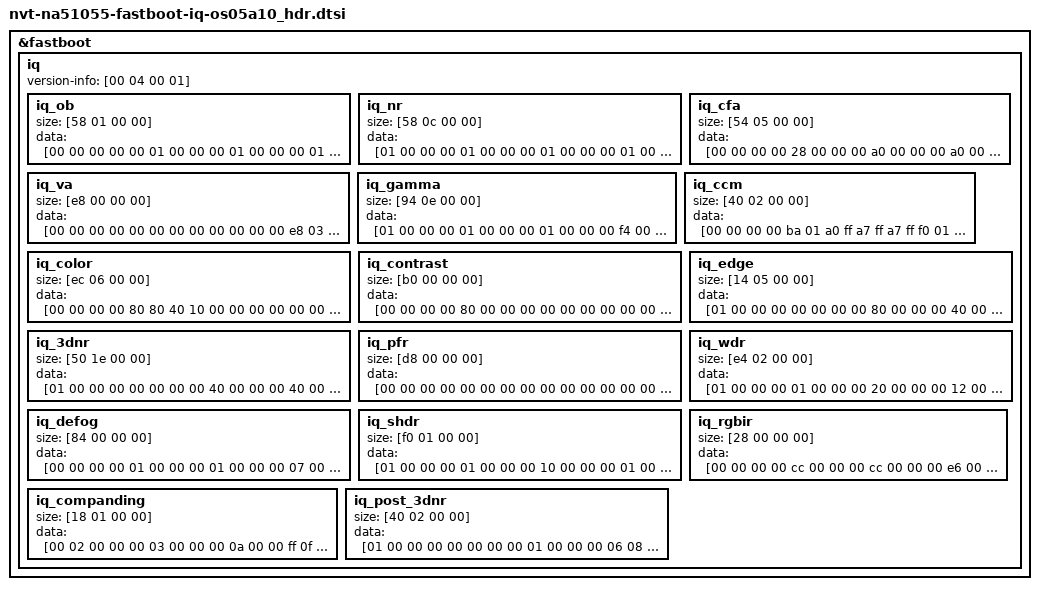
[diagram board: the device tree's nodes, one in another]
/*
 * Novatek Ltd. NA51055 BSP part of dts
 *
 * Cortex-A9
 *
 */

&fastboot {
	iq {
		version-info = [00 04 00 01];
		iq_ob {
			size = [58 01 00 00];
			data = [00 00 00 00 00 01 00 00 00 01 00 00 00 01 00 00 00 01 00 00 00 01 00 00 00 01 00 00 00 01 00 00 00 01 00 00 00 01 00 00 00 01 00 00 00 01 00 00 00 01 00 00 00 01 00 00 00 01 00 00 00 01 00 00 00 01 00 00 00 01 00 00 00 01 00 00 00 01 00 00 00 01 00 00 00 01 00 00 00 01 00 00 00 01 00 00 00 01 00 00 00 01 00 00 00 01 00 00 00 01 00 00 00 01 00 00 00 01 00 00 00 01 00 00 00 01 00 00 00 01 00 00 00 01 00 00 00 01 00 00 00 01 00 00 00 01 00 00 00 01 00 00 00 01 00 00 00 01 00 00 00 01 00 00 00 01 00 00 00 01 00 00 00 01 00 00 00 01 00 00 00 01 00 00 00 01 00 00 00 01 00 00 00 01 00 00 00 01 00 00 00 01 00 00 00 01 00 00 00 01 00 00 00 01 00 00 00 01 00 00 00 01 00 00 00 01 00 00 00 01 00 00 00 01 00 00 00 01 00 00 00 01 00 00 08 01 00 00 08 01 00 00 08 01 00 00 08 01 00 00 08 01 00 00 00 01 00 00 00 01 00 00 00 01 00 00 00 01 00 00 00 01 00 00 00 01 00 00 00 01 00 00 00 01 00 00 00 01 00 00 00 01 00 00 00 01 00 00 00 01 00 00 00 01 00 00 00 01 00 00 00 01 00 00 00 01 00 00 00 01 00 00 00 01 00 00 00 01 00 00 00 01 00 00];
		};
		iq_nr {
			size = [58 0c 00 00];
			data = [01 00 00 00 01 00 00 00 01 00 00 00 01 00 00 00 01 00 00 00 00 00 00 00 00 00 00 00 00 01 00 00 00 00 00 00 ff 0f 00 00 ff 0f 00 00 ff 0f 00 00 ff 0f 00 00 ff 0f 00 00 ff 0f 00 00 ff 0f 00 00 ff 0f 00 00 ff 0f 00 00 ff 0f 00 00 00 01 80 00 00 00 00 00 00 00 00 00 00 00 00 00 00 00 00 00 00 00 00 00 00 00 00 00 00 00 00 00 00 00 00 00 00 00 00 00 00 00 00 00 00 00 00 00 00 00 00 00 00 00 00 00 00 00 00 00 00 00 00 00 00 00 00 00 00 00 00 00 00 00 00 00 00 00 00 00 00 00 00 00 00 00 00 00 00 00 00 00 00 00 00 00 00 00 00 00 00 00 00 00 80 00 00 00 00 00 00 00 00 00 00 00 00 00 00 00 00 00 00 00 00 00 00 00 00 00 00 00 02 00 00 00 02 00 00 00 00 00 00 00 c6 02 00 00 0c 04 00 00 af 06 00 00 3d 09 00 00 41 0f 00 00 c6 02 00 00 0c 04 00 00 af 06 00 00 3d 09 00 00 41 0f 00 00 00 00 80 00 00 00 00 00 00 00 00 00 01 00 00 00 01 00 00 00 01 00 00 00 02 00 00 00 01 00 00 00 01 00 00 00 01 00 00 00 02 00 00 00 02 00 00 00 02 00 00 00 02 00 00 00 03 00 00 00 03 00 00 00 03 00 00 00 03 00 00 00 03 00 00 00 04 00 00 00 04 00 00 00 04 00 00 00 04 00 00 00 04 00 00 00 00 00 00 00 40 00 00 00 50 00 00 00 08 00 00 00 08 00 00 00 08 00 00 00 08 00 00 00 00 00 00 00 00 00 00 00 00 00 00 00 00 00 00 00 00 00 00 00 c6 02 00 00 0c 04 00 00 af 06 00 00 3d 09 00 00 41 0f 00 00 c6 02 00 00 0c 04 00 00 af 06 00 00 3d 09 00 00 41 0f 00 00 00 00 80 00 00 00 00 00 01 00 00 00 01 00 00 00 02 00 00 00 02 00 00 00 03 00 00 00 01 00 00 00 02 00 00 00 02 00 00 00 03 00 00 00 04 00 00 00 04 00 00 00 04 00 00 00 05 00 00 00 05 00 00 00 06 00 00 00 06 00 00 00 06 00 00 00 06 00 00 00 07 00 00 00 07 00 00 00 07 00 00 00 08 00 00 00 00 00 00 00 40 00 00 00 50 00 00 00 08 00 00 00 08 00 00 00 08 00 00 00 08 00 00 00 00 00 00 00 04 00 00 00 01 00 00 00 01 00 00 00 00 00 00 00 c6 02 00 00 0c 04 00 00 af 06 00 00 3d 09 00 00 41 0f 00 00 c6 02 00 00 0c 04 00 00 af 06 00 00 3d 09 00 00 41 0f 00 00 00 00 80 00 00 00 00 00 01 00 00 00 02 00 00 00 03 00 00 00 03 00 00 00 04 00 00 00 01 00 00 00 03 00 00 00 04 00 00 00 05 00 00 00 06 00 00 00 07 00 00 00 07 00 00 00 08 00 00 00 09 00 00 00 09 00 00 00 0a 00 00 00 0a 00 00 00 0b 00 00 00 0b 00 00 00 0b 00 00 00 0c 00 00 00 0c 00 00 00 00 00 00 00 40 00 00 00 50 00 00 00 08 00 00 00 08 00 00 00 08 00 00 00 08 00 00 00 00 00 00 00 10 00 00 00 01 00 00 00 01 00 00 00 00 00 00 00 c6 02 00 00 0c 04 00 00 af 06 00 00 3d 09 00 00 41 0f 00 00 c6 02 00 00 0c 04 00 00 af 06 00 00 3d 09 00 00 41 0f 00 00 09 00 80 00 00 00 00 00 02 00 00 00 03 00 00 00 04 00 00 00 05 00 00 00 07 00 00 00 01 00 00 00 04 00 00 00 05 00 00 00 06 00 00 00 08 00 00 00 08 00 00 00 09 00 00 00 0a 00 00 00 0b 00 00 00 0c 00 00 00 0c 00 00 00 0d 00 00 00 0d 00 00 00 0e 00 00 00 0e 00 00 00 0f 00 00 00 10 00 00 00 00 00 00 00 20 00 00 00 5a 00 00 00 08 00 00 00 08 00 00 00 08 00 00 00 08 00 00 00 00 00 00 00 10 00 00 00 01 00 00 00 01 00 00 00 00 00 00 00 c6 02 00 00 0c 04 00 00 af 06 00 00 3d 09 00 00 41 0f 00 00 c6 02 00 00 0c 04 00 00 af 06 00 00 3d 09 00 00 41 0f 00 00 09 00 80 00 00 00 00 00 03 00 00 00 04 00 00 00 05 00 00 00 06 00 00 00 09 00 00 00 01 00 00 00 05 00 00 00 07 00 00 00 09 00 00 00 0b 00 00 00 0c 00 00 00 0d 00 00 00 0e 00 00 00 0f 00 00 00 10 00 00 00 11 00 00 00 12 00 00 00 13 00 00 00 14 00 00 00 14 00 00 00 15 00 00 00 16 00 00 00 00 00 00 00 20 00 00 00 50 00 00 00 08 00 00 00 08 00 00 00 08 00 00 00 08 00 00 00 0a 00 00 00 10 00 00 00 01 00 00 00 01 00 00 00 00 00 00 00 c6 02 00 00 0c 04 00 00 af 06 00 00 3d 09 00 00 41 0f 00 00 c6 02 00 00 0c 04 00 00 af 06 00 00 3d 09 00 00 41 0f 00 00 09 00 80 00 00 00 00 00 04 00 00 00 06 00 00 00 07 00 00 00 08 00 00 00 0c 00 00 00 01 00 00 00 07 00 00 00 0a 00 00 00 0c 00 00 00 0e 00 00 00 10 00 00 00 11 00 00 00 13 00 00 00 14 00 00 00 15 00 00 00 16 00 00 00 17 00 00 00 18 00 00 00 19 00 00 00 1a 00 00 00 1b 00 00 00 1c 00 00 00 04 00 00 00 20 00 00 00 30 00 00 00 0a 00 00 00 0a 00 00 00 10 00 00 00 10 00 00 00 10 00 00 00 14 00 00 00 01 00 00 00 01 00 00 00 00 00 00 00 c6 02 00 00 0c 04 00 00 af 06 00 00 3d 09 00 00 41 0f 00 00 c6 02 00 00 0c 04 00 00 af 06 00 00 3d 09 00 00 41 0f 00 00 09 00 80 00 00 00 00 00 06 00 00 00 09 00 00 00 0b 00 00 00 0c 00 00 00 12 00 00 00 01 00 00 00 0c 00 00 00 11 00 00 00 15 00 00 00 18 00 00 00 1b 00 00 00 1e 00 00 00 20 00 00 00 23 00 00 00 25 00 00 00 27 00 00 00 29 00 00 00 2a 00 00 00 2c 00 00 00 2e 00 00 00 30 00 00 00 31 00 00 00 06 00 00 00 20 00 00 00 30 00 00 00 0a 00 00 00 0a 00 00 00 10 00 00 00 18 00 00 00 10 00 00 00 14 00 00 00 01 00 00 00 01 00 00 00 00 00 00 00 c6 02 00 00 0c 04 00 00 af 06 00 00 3d 09 00 00 41 0f 00 00 c6 02 00 00 0c 04 00 00 af 06 00 00 3d 09 00 00 41 0f 00 00 09 00 80 00 00 00 00 00 07 00 00 00 0b 00 00 00 0d 00 00 00 0f 00 00 00 16 00 00 00 01 00 00 00 10 00 00 00 17 00 00 00 1c 00 00 00 20 00 00 00 24 00 00 00 28 00 00 00 2b 00 00 00 2e 00 00 00 31 00 00 00 33 00 00 00 36 00 00 00 38 00 00 00 3b 00 00 00 3d 00 00 00 3f 00 00 00 41 00 00 00 08 00 00 00 20 00 00 00 20 00 00 00 10 00 00 00 10 00 00 00 10 00 00 00 10 00 00 00 10 00 00 00 18 00 00 00 01 00 00 00 01 00 00 00 00 00 00 00 c6 02 00 00 0c 04 00 00 af 06 00 00 3d 09 00 00 41 0f 00 00 c6 02 00 00 0c 04 00 00 af 06 00 00 3d 09 00 00 41 0f 00 00 09 00 80 00 00 00 00 00 0d 00 00 00 12 00 00 00 16 00 00 00 1a 00 00 00 25 00 00 00 00 00 00 00 18 00 00 00 21 00 00 00 29 00 00 00 30 00 00 00 35 00 00 00 3a 00 00 00 3f 00 00 00 43 00 00 00 48 00 00 00 4b 00 00 00 4f 00 00 00 53 00 00 00 56 00 00 00 59 00 00 00 5c 00 00 00 60 00 00 00 00 00 00 00 20 00 00 00 20 00 00 00 10 00 00 00 10 00 00 00 10 00 00 00 10 00 00 00 00 00 00 00 12 00 00 00 02 00 00 00 03 00 00 00 00 00 00 00 c6 02 00 00 0c 04 00 00 af 06 00 00 3d 09 00 00 41 0f 00 00 c6 02 00 00 0c 04 00 00 af 06 00 00 3d 09 00 00 41 0f 00 00 09 00 80 00 00 00 00 00 16 00 00 00 1f 00 00 00 26 00 00 00 2c 00 00 00 3e 00 00 00 00 00 00 00 1e 00 00 00 2a 00 00 00 34 00 00 00 3c 00 00 00 43 00 00 00 4a 00 00 00 50 00 00 00 55 00 00 00 5b 00 00 00 60 00 00 00 64 00 00 00 69 00 00 00 6d 00 00 00 71 00 00 00 75 00 00 00 79 00 00 00 00 00 00 00 20 00 00 00 40 00 00 00 10 00 00 00 10 00 00 00 10 00 00 00 10 00 00 00 00 00 00 00 12 00 00 00 02 00 00 00 03 00 00 00 00 00 00 00 c6 02 00 00 0c 04 00 00 af 06 00 00 3d 09 00 00 41 0f 00 00 c6 02 00 00 0c 04 00 00 af 06 00 00 3d 09 00 00 41 0f 00 00 09 00 80 00 00 00 00 00 10 00 00 00 16 00 00 00 1c 00 00 00 20 00 00 00 2d 00 00 00 00 00 00 00 17 00 00 00 20 00 00 00 28 00 00 00 2e 00 00 00 33 00 00 00 38 00 00 00 3d 00 00 00 41 00 00 00 45 00 00 00 49 00 00 00 4c 00 00 00 50 00 00 00 53 00 00 00 56 00 00 00 59 00 00 00 5c 00 00 00 00 00 00 00 20 00 00 00 40 00 00 00 10 00 00 00 10 00 00 00 10 00 00 00 10 00 00 00 18 00 00 00 14 00 00 00 01 00 00 00 01 00 00 00 00 00 00 00 c6 02 00 00 0c 04 00 00 af 06 00 00 3d 09 00 00 41 0f 00 00 c6 02 00 00 0c 04 00 00 af 06 00 00 3d 09 00 00 41 0f 00 00 09 00 80 00 00 00 00 00 21 00 00 00 2f 00 00 00 3a 00 00 00 43 00 00 00 5f 00 00 00 00 00 00 00 27 00 00 00 38 00 00 00 44 00 00 00 4f 00 00 00 58 00 00 00 60 00 00 00 68 00 00 00 70 00 00 00 76 00 00 00 7d 00 00 00 83 00 00 00 89 00 00 00 8e 00 00 00 94 00 00 00 99 00 00 00 9e 00 00 00 00 00 00 00 20 00 00 00 20 00 00 00 10 00 00 00 10 00 00 00 10 00 00 00 10 00 00 00 1a 00 00 00 14 00 00 00 01 00 00 00 01 00 00 00 00 00 00 00 c6 02 00 00 0c 04 00 00 af 06 00 00 3d 09 00 00 41 0f 00 00 c6 02 00 00 0c 04 00 00 af 06 00 00 3d 09 00 00 41 0f 00 00 09 00 80 00 00 00 00 00 2e 00 00 00 42 00 00 00 51 00 00 00 5d 00 00 00 84 00 00 00 00 00 00 00 32 00 00 00 47 00 00 00 57 00 00 00 65 00 00 00 71 00 00 00 7c 00 00 00 86 00 00 00 8f 00 00 00 98 00 00 00 a0 00 00 00 a8 00 00 00 af 00 00 00 b7 00 00 00 be 00 00 00 c4 00 00 00 cb 00 00 00 00 00 00 00 20 00 00 00 20 00 00 00 10 00 00 00 10 00 00 00 10 00 00 00 10 00 00 00 1c 00 00 00 16 00 00 00 01 00 00 00 01 00 00 00 00 00 00 00 c6 02 00 00 0c 04 00 00 af 06 00 00 3d 09 00 00 41 0f 00 00 c6 02 00 00 0c 04 00 00 af 06 00 00 3d 09 00 00 41 0f 00 00 09 00 80 00 00 00 00 00 2e 00 00 00 42 00 00 00 51 00 00 00 5d 00 00 00 84 00 00 00 00 00 00 00 32 00 00 00 47 00 00 00 57 00 00 00 65 00 00 00 71 00 00 00 7c 00 00 00 86 00 00 00 8f 00 00 00 98 00 00 00 a0 00 00 00 a8 00 00 00 af 00 00 00 b7 00 00 00 be 00 00 00 c4 00 00 00 cb 00 00 00 00 00 00 00 20 00 00 00 20 00 00 00 10 00 00 00 10 00 00 00 10 00 00 00 10 00 00 00 1c 00 00 00 16 00 00 00 01 00 00 00 01 00 00 00 00 00 00 00 c6 02 00 00 0c 04 00 00 af 06 00 00 3d 09 00 00 41 0f 00 00 c6 02 00 00 0c 04 00 00 af 06 00 00 3d 09 00 00 41 0f 00 00 09 00 80 00 00 00 00 00 2e 00 00 00 42 00 00 00 51 00 00 00 5d 00 00 00 84 00 00 00 00 00 00 00 32 00 00 00 47 00 00 00 57 00 00 00 65 00 00 00 71 00 00 00 7c 00 00 00 86 00 00 00 8f 00 00 00 98 00 00 00 a0 00 00 00 a8 00 00 00 af 00 00 00 b7 00 00 00 be 00 00 00 c4 00 00 00 cb 00 00 00 00 00 00 00 20 00 00 00 20 00 00 00 10 00 00 00 10 00 00 00 10 00 00 00 10 00 00 00 1c 00 00 00 16 00 00 00 01 00 00 00 01 00 00 00 00 00 00 00 c6 02 00 00 0c 04 00 00 af 06 00 00 3d 09 00 00 41 0f 00 00 c6 02 00 00 0c 04 00 00 af 06 00 00 3d 09 00 00 41 0f 00 00 09 00 80 00 00 00 00 00 2e 00 00 00 42 00 00 00 51 00 00 00 5d 00 00 00 84 00 00 00 00 00 00 00 32 00 00 00 47 00 00 00 57 00 00 00 65 00 00 00 71 00 00 00 7c 00 00 00 86 00 00 00 8f 00 00 00 98 00 00 00 a0 00 00 00 a8 00 00 00 af 00 00 00 b7 00 00 00 be 00 00 00 c4 00 00 00 cb 00 00 00 00 00 00 00 20 00 00 00 20 00 00 00 10 00 00 00 10 00 00 00 10 00 00 00 10 00 00 00 1c 00 00 00 16 00 00 00 01 00 00 00 01 00 00 00];
		};
		iq_cfa {
			size = [54 05 00 00];
			data = [00 00 00 00 28 00 00 00 a0 00 00 00 a0 00 00 00 40 00 00 00 0f 00 00 00 0f 00 00 00 07 00 00 00 04 00 00 00 03 00 00 00 02 00 00 00 02 00 00 00 01 00 00 00 01 00 00 00 01 00 00 00 01 00 00 00 00 00 00 00 00 00 00 00 00 00 00 00 00 00 00 00 00 00 00 00 28 00 00 00 a0 00 00 00 a0 00 00 00 40 00 00 00 0f 00 00 00 0f 00 00 00 07 00 00 00 04 00 00 00 03 00 00 00 02 00 00 00 02 00 00 00 01 00 00 00 01 00 00 00 01 00 00 00 01 00 00 00 00 00 00 00 00 00 00 00 00 00 00 00 00 00 00 00 00 00 00 00 28 00 00 00 a0 00 00 00 a0 00 00 00 40 00 00 00 0f 00 00 00 0f 00 00 00 07 00 00 00 04 00 00 00 03 00 00 00 02 00 00 00 02 00 00 00 01 00 00 00 01 00 00 00 01 00 00 00 01 00 00 00 00 00 00 00 00 00 00 00 00 00 00 00 00 00 00 00 00 00 00 00 28 00 00 00 a0 00 00 00 a0 00 00 00 40 00 00 00 0f 00 00 00 0f 00 00 00 07 00 00 00 04 00 00 00 03 00 00 00 02 00 00 00 02 00 00 00 01 00 00 00 01 00 00 00 01 00 00 00 01 00 00 00 00 00 00 00 00 00 00 00 00 00 00 00 00 00 00 00 00 00 00 00 28 00 00 00 a0 00 00 00 a0 00 00 00 40 00 00 00 0f 00 00 00 0f 00 00 00 07 00 00 00 04 00 00 00 03 00 00 00 02 00 00 00 02 00 00 00 01 00 00 00 01 00 00 00 01 00 00 00 01 00 00 00 00 00 00 00 00 00 00 00 00 00 00 00 00 00 00 00 00 00 00 00 28 00 00 00 a0 00 00 00 a0 00 00 00 40 00 00 00 0f 00 00 00 0f 00 00 00 07 00 00 00 04 00 00 00 03 00 00 00 02 00 00 00 02 00 00 00 01 00 00 00 01 00 00 00 01 00 00 00 01 00 00 00 00 00 00 00 00 00 00 00 00 00 00 00 00 00 00 00 00 00 00 00 28 00 00 00 a0 00 00 00 a0 00 00 00 40 00 00 00 0f 00 00 00 0f 00 00 00 07 00 00 00 04 00 00 00 03 00 00 00 02 00 00 00 02 00 00 00 01 00 00 00 01 00 00 00 01 00 00 00 01 00 00 00 00 00 00 00 00 00 00 00 00 00 00 00 00 00 00 00 00 00 00 00 28 00 00 00 a0 00 00 00 a0 00 00 00 40 00 00 00 0f 00 00 00 0f 00 00 00 07 00 00 00 04 00 00 00 03 00 00 00 02 00 00 00 02 00 00 00 01 00 00 00 01 00 00 00 01 00 00 00 01 00 00 00 00 00 00 00 00 00 00 00 00 00 00 00 00 00 00 00 00 00 00 00 28 00 00 00 a0 00 00 00 a0 00 00 00 40 00 00 00 0f 00 00 00 0f 00 00 00 07 00 00 00 04 00 00 00 03 00 00 00 02 00 00 00 02 00 00 00 01 00 00 00 01 00 00 00 01 00 00 00 01 00 00 00 00 00 00 00 00 00 00 00 00 00 00 00 00 00 00 00 00 00 00 00 28 00 00 00 a0 00 00 00 a0 00 00 00 40 00 00 00 0f 00 00 00 0f 00 00 00 07 00 00 00 04 00 00 00 03 00 00 00 02 00 00 00 02 00 00 00 01 00 00 00 01 00 00 00 01 00 00 00 01 00 00 00 00 00 00 00 00 00 00 00 00 00 00 00 00 00 00 00 00 00 00 00 28 00 00 00 a0 00 00 00 a0 00 00 00 40 00 00 00 0f 00 00 00 0f 00 00 00 07 00 00 00 04 00 00 00 03 00 00 00 02 00 00 00 02 00 00 00 01 00 00 00 01 00 00 00 01 00 00 00 01 00 00 00 00 00 00 00 00 00 00 00 00 00 00 00 00 00 00 00 00 00 00 00 28 00 00 00 a0 00 00 00 a0 00 00 00 20 00 00 00 08 00 00 00 08 00 00 00 03 00 00 00 02 00 00 00 01 00 00 00 01 00 00 00 01 00 00 00 00 00 00 00 00 00 00 00 00 00 00 00 00 00 00 00 00 00 00 00 00 00 00 00 00 00 00 00 00 00 00 00 00 00 00 00 28 00 00 00 a0 00 00 00 a0 00 00 00 20 00 00 00 08 00 00 00 08 00 00 00 03 00 00 00 02 00 00 00 01 00 00 00 01 00 00 00 01 00 00 00 00 00 00 00 00 00 00 00 00 00 00 00 00 00 00 00 00 00 00 00 00 00 00 00 00 00 00 00 00 00 00 00 00 00 00 00 28 00 00 00 a0 00 00 00 a0 00 00 00 40 00 00 00 0f 00 00 00 0f 00 00 00 07 00 00 00 04 00 00 00 03 00 00 00 02 00 00 00 02 00 00 00 01 00 00 00 01 00 00 00 01 00 00 00 01 00 00 00 00 00 00 00 00 00 00 00 00 00 00 00 00 00 00 00 00 00 00 00 28 00 00 00 a0 00 00 00 a0 00 00 00 40 00 00 00 0f 00 00 00 0f 00 00 00 07 00 00 00 04 00 00 00 03 00 00 00 02 00 00 00 02 00 00 00 01 00 00 00 01 00 00 00 01 00 00 00 01 00 00 00 00 00 00 00 00 00 00 00 00 00 00 00 00 00 00 00 00 00 00 00 28 00 00 00 a0 00 00 00 a0 00 00 00 40 00 00 00 0f 00 00 00 0f 00 00 00 07 00 00 00 04 00 00 00 03 00 00 00 02 00 00 00 02 00 00 00 01 00 00 00 01 00 00 00 01 00 00 00 01 00 00 00 00 00 00 00 00 00 00 00 00 00 00 00 00 00 00 00 00 00 00 00 28 00 00 00 a0 00 00 00 a0 00 00 00 40 00 00 00 0f 00 00 00 0f 00 00 00 07 00 00 00 04 00 00 00 03 00 00 00 02 00 00 00 02 00 00 00 01 00 00 00 01 00 00 00 01 00 00 00 01 00 00 00 00 00 00 00 00 00 00 00 00 00 00 00 00 00 00 00 00 00 00 00];
		};
		iq_va {
			size = [e8 00 00 00];
			data = [00 00 00 00 00 00 00 00 00 00 00 00 e8 03 00 00 e8 03 00 00 00 00 00 00 00 00 00 00 e8 03 00 00 e8 03 00 00 00 00 00 00 00 00 00 00 e8 03 00 00 e8 03 00 00 00 00 00 00 00 00 00 00 e8 03 00 00 e8 03 00 00 00 00 00 00 00 00 00 00 e8 03 00 00 e8 03 00 00 02 ff 00 00 03 02 00 ff 00 03 06 00 08 00 06 00 08 00 06 00 08 00 06 00 08 00 06 00 08 00 06 00 08 00 06 00 08 00 06 00 08 00 06 00 08 00 06 00 08 00 06 00 08 00 06 00 08 00 06 00 08 00 06 00 08 00 06 00 08 00 06 00 08 00 06 00 08 00 06 00 08 00 06 00 08 00 06 00 08 00 06 00 08 00 06 00 08 00 06 00 08 00 06 00 08 00 06 00 08 00 06 00 08 00 06 00 08 00 06 00 08 00 06 00 08 00 06 00 08 00 06 00 08 00 06 00 08 00 06 00 08 00 06 00 08 00 00 00];
		};
		iq_gamma {
			size = [94 0e 00 00];
			data = [01 00 00 00 01 00 00 00 01 00 00 00 f4 00 00 00 da 00 00 00 c8 00 00 00 be 00 00 00 b4 00 00 00 b4 00 00 00 b4 00 00 00 b4 00 00 00 b4 00 00 00 b4 00 00 00 b4 00 00 00 b4 00 00 00 b4 00 00 00 b9 00 00 00 bf 00 00 00 d3 00 00 00 f4 00 00 00 00 00 00 00 04 00 00 00 08 00 00 00 0c 00 00 00 10 00 00 00 14 00 00 00 18 00 00 00 1a 00 00 00 1c 00 00 00 1d 00 00 00 1e 00 00 00 1f 00 00 00 20 00 00 00 21 00 00 00 22 00 00 00 23 00 00 00 24 00 00 00 25 00 00 00 26 00 00 00 27 00 00 00 28 00 00 00 29 00 00 00 2a 00 00 00 2b 00 00 00 2c 00 00 00 2d 00 00 00 2e 00 00 00 2f 00 00 00 30 00 00 00 34 00 00 00 38 00 00 00 3c 00 00 00 02 00 00 00 02 00 00 00 02 00 00 00 02 00 00 00 02 00 00 00 02 00 00 00 01 00 00 00 01 00 00 00 00 00 00 00 00 00 00 00 00 00 00 00 00 00 00 00 00 00 00 00 00 00 00 00 00 00 00 00 00 00 00 00 00 00 00 00 00 00 00 00 00 00 00 00 00 00 00 00 00 00 00 00 00 00 00 00 00 00 00 00 00 00 00 00 00 00 00 00 00 00 00 00 00 00 00 00 00 00 00 00 02 00 00 00 02 00 00 00 02 00 00 00 02 00 00 00 00 00 00 00 00 02 00 00 43 03 00 00 2f 04 00 00 e9 04 00 00 4e 05 00 00 a6 05 00 00 f3 05 00 00 3a 06 00 00 79 06 00 00 b4 06 00 00 ea 06 00 00 1d 07 00 00 4d 07 00 00 7a 07 00 00 a5 07 00 00 ce 07 00 00 f5 07 00 00 1b 08 00 00 3f 08 00 00 61 08 00 00 83 08 00 00 a4 08 00 00 c3 08 00 00 e2 08 00 00 1d 09 00 00 54 09 00 00 8a 09 00 00 bd 09 00 00 1f 0a 00 00 79 0a 00 00 cf 0a 00 00 21 0b 00 00 6f 0b 00 00 ba 0b 00 00 03 0c 00 00 49 0c 00 00 8e 0c 00 00 d0 0c 00 00 11 0d 00 00 51 0d 00 00 8f 0d 00 00 cc 0d 00 00 08 0e 00 00 43 0e 00 00 7d 0e 00 00 b6 0e 00 00 ee 0e 00 00 26 0f 00 00 34 0f 00 00 42 0f 00 00 4f 0f 00 00 5d 0f 00 00 6b 0f 00 00 79 0f 00 00 86 0f 00 00 94 0f 00 00 a1 0f 00 00 af 0f 00 00 bc 0f 00 00 ca 0f 00 00 d7 0f 00 00 e5 0f 00 00 f2 0f 00 00 ff 0f 00 00 00 00 00 00 04 00 00 00 08 00 00 00 0c 00 00 00 10 00 00 00 14 00 00 00 18 00 00 00 1a 00 00 00 1c 00 00 00 1d 00 00 00 1e 00 00 00 1f 00 00 00 20 00 00 00 21 00 00 00 22 00 00 00 23 00 00 00 24 00 00 00 25 00 00 00 26 00 00 00 27 00 00 00 28 00 00 00 29 00 00 00 2a 00 00 00 2b 00 00 00 2c 00 00 00 2d 00 00 00 2e 00 00 00 2f 00 00 00 30 00 00 00 34 00 00 00 38 00 00 00 3c 00 00 00 02 00 00 00 02 00 00 00 02 00 00 00 02 00 00 00 02 00 00 00 02 00 00 00 01 00 00 00 01 00 00 00 00 00 00 00 00 00 00 00 00 00 00 00 00 00 00 00 00 00 00 00 00 00 00 00 00 00 00 00 00 00 00 00 00 00 00 00 00 00 00 00 00 00 00 00 00 00 00 00 00 00 00 00 00 00 00 00 00 00 00 00 00 00 00 00 00 00 00 00 00 00 00 00 00 00 00 00 00 00 00 00 02 00 00 00 02 00 00 00 02 00 00 00 02 00 00 00 05 00 00 00 00 00 00 00 00 00 00 00 57 00 00 00 ab 00 00 00 fd 00 00 00 4b 01 00 00 97 01 00 00 e1 01 00 00 28 02 00 00 6d 02 00 00 b0 02 00 00 f1 02 00 00 31 03 00 00 6e 03 00 00 aa 03 00 00 e4 03 00 00 1d 04 00 00 55 04 00 00 8a 04 00 00 be 04 00 00 f0 04 00 00 21 05 00 00 50 05 00 00 7e 05 00 00 aa 05 00 00 d5 05 00 00 1e 06 00 00 67 06 00 00 ad 06 00 00 f3 06 00 00 78 07 00 00 f8 07 00 00 72 08 00 00 e6 08 00 00 58 09 00 00 c6 09 00 00 2f 0a 00 00 95 0a 00 00 f9 0a 00 00 5b 0b 00 00 bb 0b 00 00 18 0c 00 00 73 0c 00 00 cd 0c 00 00 25 0d 00 00 7b 0d 00 00 d0 0d 00 00 23 0e 00 00 76 0e 00 00 c7 0e 00 00 db 0e 00 00 ef 0e 00 00 02 0f 00 00 17 0f 00 00 2a 0f 00 00 3e 0f 00 00 51 0f 00 00 65 0f 00 00 79 0f 00 00 8c 0f 00 00 9f 0f 00 00 b2 0f 00 00 c6 0f 00 00 d9 0f 00 00 ec 0f 00 00 ff 0f 00 00 19 00 00 00 00 00 00 00 80 00 00 00 f7 00 00 00 67 01 00 00 d0 01 00 00 33 02 00 00 90 02 00 00 e9 02 00 00 3d 03 00 00 8d 03 00 00 da 03 00 00 23 04 00 00 69 04 00 00 ac 04 00 00 ed 04 00 00 2c 05 00 00 69 05 00 00 a1 05 00 00 d8 05 00 00 0c 06 00 00 3f 06 00 00 70 06 00 00 9f 06 00 00 cc 06 00 00 f7 06 00 00 3e 07 00 00 83 07 00 00 c6 07 00 00 08 08 00 00 85 08 00 00 fb 08 00 00 6a 09 00 00 d2 09 00 00 38 0a 00 00 9a 0a 00 00 f8 0a 00 00 51 0b 00 00 a9 0b 00 00 ff 0b 00 00 52 0c 00 00 a3 0c 00 00 f2 0c 00 00 40 0d 00 00 8c 0d 00 00 d7 0d 00 00 20 0e 00 00 67 0e 00 00 ae 0e 00 00 f3 0e 00 00 05 0f 00 00 16 0f 00 00 27 0f 00 00 38 0f 00 00 49 0f 00 00 5a 0f 00 00 6b 0f 00 00 7b 0f 00 00 8c 0f 00 00 9c 0f 00 00 ad 0f 00 00 bd 0f 00 00 ce 0f 00 00 de 0f 00 00 ef 0f 00 00 ff 0f 00 00 32 00 00 00 00 00 00 00 9e 00 00 00 2e 01 00 00 b1 01 00 00 2a 02 00 00 9a 02 00 00 01 03 00 00 63 03 00 00 be 03 00 00 14 04 00 00 65 04 00 00 b3 04 00 00 fc 04 00 00 41 05 00 00 84 05 00 00 c4 05 00 00 02 06 00 00 3a 06 00 00 71 06 00 00 a6 06 00 00 d9 06 00 00 09 07 00 00 38 07 00 00 64 07 00 00 8f 07 00 00 d3 07 00 00 16 08 00 00 57 08 00 00 96 08 00 00 0d 09 00 00 7d 09 00 00 e5 09 00 00 46 0a 00 00 a6 0a 00 00 02 0b 00 00 59 0b 00 00 ac 0b 00 00 fe 0b 00 00 4d 0c 00 00 9a 0c 00 00 e5 0c 00 00 2f 0d 00 00 77 0d 00 00 bd 0d 00 00 02 0e 00 00 45 0e 00 00 87 0e 00 00 c8 0e 00 00 08 0f 00 00 18 0f 00 00 28 0f 00 00 38 0f 00 00 48 0f 00 00 57 0f 00 00 67 0f 00 00 76 0f 00 00 85 0f 00 00 95 0f 00 00 a4 0f 00 00 b4 0f 00 00 c3 0f 00 00 d2 0f 00 00 e1 0f 00 00 f0 0f 00 00 ff 0f 00 00 4b 00 00 00 00 00 00 00 e0 00 00 00 9e 01 00 00 43 02 00 00 d5 02 00 00 58 03 00 00 cf 03 00 00 3b 04 00 00 9e 04 00 00 fb 04 00 00 51 05 00 00 a1 05 00 00 ed 05 00 00 33 06 00 00 77 06 00 00 b7 06 00 00 f5 06 00 00 2c 07 00 00 61 07 00 00 95 07 00 00 c6 07 00 00 f4 07 00 00 21 08 00 00 4b 08 00 00 74 08 00 00 b3 08 00 00 f1 08 00 00 2d 09 00 00 67 09 00 00 d4 09 00 00 3a 0a 00 00 98 0a 00 00 ee 0a 00 00 44 0b 00 00 96 0b 00 00 e4 0b 00 00 2e 0c 00 00 76 0c 00 00 bc 0c 00 00 01 0d 00 00 43 0d 00 00 84 0d 00 00 c3 0d 00 00 01 0e 00 00 3e 0e 00 00 7a 0e 00 00 b4 0e 00 00 ed 0e 00 00 26 0f 00 00 34 0f 00 00 42 0f 00 00 4f 0f 00 00 5d 0f 00 00 6b 0f 00 00 79 0f 00 00 86 0f 00 00 94 0f 00 00 a2 0f 00 00 af 0f 00 00 bc 0f 00 00 ca 0f 00 00 d7 0f 00 00 e4 0f 00 00 f2 0f 00 00 ff 0f 00 00 64 00 00 00 00 00 00 00 00 02 00 00 43 03 00 00 2f 04 00 00 e9 04 00 00 83 05 00 00 06 06 00 00 78 06 00 00 de 06 00 00 37 07 00 00 89 07 00 00 d4 07 00 00 19 08 00 00 4f 08 00 00 83 08 00 00 b4 08 00 00 e4 08 00 00 0d 09 00 00 35 09 00 00 5c 09 00 00 82 09 00 00 a7 09 00 00 ca 09 00 00 ec 09 00 00 0e 0a 00 00 4c 0a 00 00 86 0a 00 00 bc 0a 00 00 ed 0a 00 00 4e 0b 00 00 a7 0b 00 00 f6 0b 00 00 3c 0c 00 00 81 0c 00 00 c2 0c 00 00 00 0d 00 00 3b 0d 00 00 73 0d 00 00 a9 0d 00 00 dd 0d 00 00 0f 0e 00 00 3e 0e 00 00 6d 0e 00 00 9a 0e 00 00 c6 0e 00 00 f0 0e 00 00 1a 0f 00 00 42 0f 00 00 69 0f 00 00 73 0f 00 00 7d 0f 00 00 86 0f 00 00 90 0f 00 00 9a 0f 00 00 a3 0f 00 00 ac 0f 00 00 b6 0f 00 00 bf 0f 00 00 c8 0f 00 00 d1 0f 00 00 db 0f 00 00 e4 0f 00 00 ed 0f 00 00 f6 0f 00 00 ff 0f 00 00 00 00 00 00 0d 00 00 00 1a 00 00 00 27 00 00 00 34 00 00 00 3f 00 00 00 4a 00 00 00 57 00 00 00 64 00 00 00 71 00 00 00 7d 00 00 00 89 00 00 00 95 00 00 00 a0 00 00 00 aa 00 00 00 b5 00 00 00 bf 00 00 00 c6 00 00 00 ce 00 00 00 d6 00 00 00 de 00 00 00 e6 00 00 00 ee 00 00 00 f6 00 00 00 fe 00 00 00 06 01 00 00 0d 01 00 00 15 01 00 00 1c 01 00 00 23 01 00 00 2a 01 00 00 31 01 00 00 38 01 00 00 3f 01 00 00 47 01 00 00 4e 01 00 00 56 01 00 00 5e 01 00 00 66 01 00 00 6e 01 00 00 76 01 00 00 7e 01 00 00 86 01 00 00 8e 01 00 00 97 01 00 00 9f 01 00 00 a8 01 00 00 b1 01 00 00 b8 01 00 00 c0 01 00 00 c7 01 00 00 cf 01 00 00 d6 01 00 00 de 01 00 00 e5 01 00 00 ed 01 00 00 f4 01 00 00 fc 01 00 00 03 02 00 00 0b 02 00 00 13 02 00 00 1a 02 00 00 22 02 00 00 29 02 00 00 31 02 00 00 39 02 00 00 40 02 00 00 48 02 00 00 50 02 00 00 58 02 00 00 60 02 00 00 68 02 00 00 70 02 00 00 77 02 00 00 7f 02 00 00 87 02 00 00 8f 02 00 00 97 02 00 00 9f 02 00 00 a7 02 00 00 af 02 00 00 b8 02 00 00 c0 02 00 00 c8 02 00 00 d0 02 00 00 d8 02 00 00 e0 02 00 00 e8 02 00 00 ef 02 00 00 f7 02 00 00 ff 02 00 00 07 03 00 00 0f 03 00 00 16 03 00 00 1e 03 00 00 26 03 00 00 2d 03 00 00 35 03 00 00 3c 03 00 00 44 03 00 00 4b 03 00 00 52 03 00 00 59 03 00 00 60 03 00 00 67 03 00 00 6e 03 00 00 75 03 00 00 7c 03 00 00 83 03 00 00 89 03 00 00 90 03 00 00 97 03 00 00 9d 03 00 00 a4 03 00 00 aa 03 00 00 b0 03 00 00 b6 03 00 00 bd 03 00 00 c3 03 00 00 c9 03 00 00 cf 03 00 00 d5 03 00 00 db 03 00 00 e1 03 00 00 e7 03 00 00 ed 03 00 00 f3 03 00 00 f9 03 00 00 ff 03 00 00 06 00 00 00 00 00 00 00 1b 00 00 00 2c 00 00 00 3c 00 00 00 49 00 00 00 56 00 00 00 63 00 00 00 6f 00 00 00 7a 00 00 00 85 00 00 00 90 00 00 00 9b 00 00 00 a6 00 00 00 b0 00 00 00 ba 00 00 00 c5 00 00 00 cf 00 00 00 d9 00 00 00 e3 00 00 00 ed 00 00 00 f7 00 00 00 01 01 00 00 0a 01 00 00 14 01 00 00 1e 01 00 00 27 01 00 00 31 01 00 00 3b 01 00 00 44 01 00 00 4e 01 00 00 57 01 00 00 61 01 00 00 6a 01 00 00 73 01 00 00 7d 01 00 00 86 01 00 00 8f 01 00 00 98 01 00 00 a2 01 00 00 ab 01 00 00 b4 01 00 00 bd 01 00 00 c6 01 00 00 cf 01 00 00 d8 01 00 00 e1 01 00 00 ea 01 00 00 f2 01 00 00 fb 01 00 00 04 02 00 00 0c 02 00 00 15 02 00 00 1e 02 00 00 26 02 00 00 2e 02 00 00 37 02 00 00 3f 02 00 00 47 02 00 00 50 02 00 00 58 02 00 00 60 02 00 00 68 02 00 00 70 02 00 00 78 02 00 00 7f 02 00 00 87 02 00 00 8f 02 00 00 97 02 00 00 9e 02 00 00 a6 02 00 00 ad 02 00 00 b4 02 00 00 bc 02 00 00 c3 02 00 00 ca 02 00 00 d1 02 00 00 d8 02 00 00 df 02 00 00 e6 02 00 00 ed 02 00 00 f4 02 00 00 fa 02 00 00 01 03 00 00 08 03 00 00 0e 03 00 00 15 03 00 00 1b 03 00 00 21 03 00 00 28 03 00 00 2e 03 00 00 34 03 00 00 3a 03 00 00 40 03 00 00 46 03 00 00 4c 03 00 00 52 03 00 00 58 03 00 00 5e 03 00 00 64 03 00 00 69 03 00 00 6f 03 00 00 75 03 00 00 7a 03 00 00 80 03 00 00 85 03 00 00 8b 03 00 00 90 03 00 00 95 03 00 00 9b 03 00 00 a0 03 00 00 a5 03 00 00 aa 03 00 00 af 03 00 00 b5 03 00 00 ba 03 00 00 bf 03 00 00 c4 03 00 00 c9 03 00 00 ce 03 00 00 d3 03 00 00 d8 03 00 00 dd 03 00 00 e2 03 00 00 e7 03 00 00 ec 03 00 00 f0 03 00 00 f5 03 00 00 fa 03 00 00 ff 03 00 00 04 00 00 00 00 00 00 00 25 00 00 00 49 00 00 00 6b 00 00 00 8b 00 00 00 a9 00 00 00 c6 00 00 00 e1 00 00 00 f1 00 00 00 01 01 00 00 11 01 00 00 21 01 00 00 30 01 00 00 3e 01 00 00 4d 01 00 00 5b 01 00 00 68 01 00 00 75 01 00 00 82 01 00 00 8f 01 00 00 9b 01 00 00 a6 01 00 00 b1 01 00 00 bc 01 00 00 c7 01 00 00 d1 01 00 00 db 01 00 00 e4 01 00 00 ed 01 00 00 f6 01 00 00 fe 01 00 00 06 02 00 00 0d 02 00 00 14 02 00 00 1b 02 00 00 22 02 00 00 29 02 00 00 30 02 00 00 36 02 00 00 3d 02 00 00 44 02 00 00 4b 02 00 00 52 02 00 00 59 02 00 00 5f 02 00 00 66 02 00 00 6d 02 00 00 73 02 00 00 7a 02 00 00 80 02 00 00 87 02 00 00 8d 02 00 00 93 02 00 00 9a 02 00 00 a0 02 00 00 a6 02 00 00 ac 02 00 00 b3 02 00 00 b9 02 00 00 bf 02 00 00 c5 02 00 00 cb 02 00 00 d1 02 00 00 d7 02 00 00 dd 02 00 00 e3 02 00 00 e8 02 00 00 ee 02 00 00 f4 02 00 00 fa 02 00 00 ff 02 00 00 04 03 00 00 09 03 00 00 0e 03 00 00 13 03 00 00 18 03 00 00 1d 03 00 00 21 03 00 00 26 03 00 00 2b 03 00 00 30 03 00 00 35 03 00 00 3a 03 00 00 3e 03 00 00 43 03 00 00 48 03 00 00 4d 03 00 00 51 03 00 00 56 03 00 00 5b 03 00 00 5f 03 00 00 64 03 00 00 68 03 00 00 6d 03 00 00 72 03 00 00 76 03 00 00 7b 03 00 00 7f 03 00 00 84 03 00 00 88 03 00 00 8c 03 00 00 91 03 00 00 95 03 00 00 99 03 00 00 9e 03 00 00 a2 03 00 00 a6 03 00 00 ab 03 00 00 af 03 00 00 b3 03 00 00 b7 03 00 00 bb 03 00 00 bf 03 00 00 c4 03 00 00 c8 03 00 00 cc 03 00 00 d0 03 00 00 d4 03 00 00 d8 03 00 00 dc 03 00 00 e0 03 00 00 e4 03 00 00 e8 03 00 00 eb 03 00 00 ef 03 00 00 f3 03 00 00 f7 03 00 00 fb 03 00 00 ff 03 00 00];
		};
		iq_ccm {
			size = [40 02 00 00];
			data = [00 00 00 00 ba 01 a0 ff a7 ff a7 ff f0 01 6a ff 0c 00 38 ff bb 01 80 80 80 80 80 80 80 80 80 80 80 80 80 80 80 80 80 80 80 80 80 80 80 80 00 00 00 00 00 00 00 00 00 00 00 00 00 00 00 00 00 00 00 00 00 00 00 00 00 00 00 00 00 00 00 00 00 00 00 00 00 00 00 00 00 00 00 00 00 00 00 00 00 00 00 00 00 00 00 00 00 00 00 00 00 00 00 00 00 00 00 00 00 00 00 00 00 00 00 00 00 00 00 00 00 00 00 00 00 00 00 00 00 00 00 00 00 00 00 00 00 00 64 19 00 00 ba 01 a0 ff a7 ff a7 ff f0 01 6a ff 0c 00 38 ff bb 01 80 80 80 80 80 80 80 80 80 80 80 80 80 80 80 80 80 80 80 80 80 80 80 80 00 00 00 00 00 00 00 00 00 00 00 00 00 00 00 00 00 00 00 00 00 00 00 00 00 00 00 00 00 00 00 00 00 00 00 00 00 00 00 00 00 00 00 00 00 00 00 00 00 00 00 00 00 00 00 00 00 00 00 00 00 00 00 00 00 00 00 00 00 00 00 00 00 00 00 00 00 00 00 00 00 00 00 00 00 00 00 00 00 00 00 00 00 00 00 00 00 00 74 0e 00 00 52 01 fb ff b4 ff 69 ff e8 01 b0 ff 01 00 33 ff cc 01 80 80 80 80 80 80 80 80 80 80 80 80 80 80 80 80 80 80 80 80 80 80 80 80 00 00 00 00 00 00 00 00 00 00 00 00 00 00 00 00 00 00 00 00 00 00 00 00 00 00 00 00 00 00 00 00 00 00 00 00 00 00 00 00 00 00 00 00 00 00 00 00 00 00 00 00 00 00 00 00 00 00 00 00 00 00 00 00 00 00 00 00 00 00 00 00 00 00 00 00 00 00 00 00 00 00 00 00 00 00 00 00 00 00 00 00 00 00 00 00 00 00 f0 0a 00 00 f2 00 76 00 97 ff 59 ff f5 01 b3 ff f4 ff fb fe 11 02 80 80 80 80 80 80 80 80 80 80 80 80 80 80 80 80 80 80 80 80 80 80 80 80 00 00 00 00 00 00 00 00 00 00 00 00 00 00 00 00 00 00 00 00 00 00 00 00 00 00 00 00 00 00 00 00 00 00 00 00 00 00 00 00 00 00 00 00 00 00 00 00 00 00 00 00 00 00 00 00 00 00 00 00 00 00 00 00 00 00 00 00 00 00 00 00 00 00 00 00 00 00 00 00 00 00 00 00 00 00 00 00 00 00 00 00 00 00 00 00 00 00];
		};
		iq_color {
			size = [ec 06 00 00];
			data = [00 00 00 00 80 80 40 10 00 00 00 00 00 00 00 00 00 00 00 00 00 14 0f 0a 05 00 00 00 00 00 00 00 00 00 05 0a 0f 00 00 00 80 00 00 00 80 00 00 00 80 00 00 00 80 00 00 00 80 00 00 00 80 00 00 00 80 00 00 00 80 00 00 00 80 00 00 00 80 00 00 00 80 00 00 00 80 00 00 00 80 00 00 00 80 00 00 00 80 00 00 00 80 00 00 00 80 00 00 00 8c 80 40 10 00 00 00 00 00 00 00 00 00 00 00 00 00 14 0f 0a 05 00 00 00 00 00 00 00 00 00 05 0a 0f 00 00 00 80 00 00 00 80 00 00 00 80 00 00 00 80 00 00 00 80 00 00 00 80 00 00 00 80 00 00 00 80 00 00 00 80 00 00 00 80 00 00 00 80 00 00 00 80 00 00 00 80 00 00 00 80 00 00 00 80 00 00 00 80 00 00 00 80 00 00 00 8c 80 40 10 00 00 00 00 00 00 00 00 00 00 00 00 00 14 0f 0a 05 00 00 00 00 00 00 00 00 00 05 0a 0f 00 00 00 80 00 00 00 80 00 00 00 80 00 00 00 80 00 00 00 80 00 00 00 80 00 00 00 80 00 00 00 80 00 00 00 80 00 00 00 80 00 00 00 80 00 00 00 80 00 00 00 80 00 00 00 80 00 00 00 80 00 00 00 80 00 00 00 80 00 00 00 8c 80 40 10 00 00 00 00 00 00 00 00 00 00 00 00 00 14 0f 0a 05 00 00 00 00 00 00 00 00 00 05 0a 0f 00 00 00 80 00 00 00 80 00 00 00 80 00 00 00 80 00 00 00 80 00 00 00 80 00 00 00 80 00 00 00 80 00 00 00 80 00 00 00 80 00 00 00 80 00 00 00 80 00 00 00 80 00 00 00 80 00 00 00 80 00 00 00 80 00 00 00 80 00 00 00 87 80 40 10 00 00 00 00 00 00 00 00 00 00 00 00 00 14 0f 0a 05 00 00 00 00 00 00 00 00 00 05 0a 0f 00 00 00 80 00 00 00 80 00 00 00 80 00 00 00 80 00 00 00 80 00 00 00 80 00 00 00 80 00 00 00 80 00 00 00 80 00 00 00 80 00 00 00 80 00 00 00 80 00 00 00 80 00 00 00 80 00 00 00 80 00 00 00 80 00 00 00 80 00 00 00 87 80 40 10 00 00 00 00 00 00 00 00 00 00 00 00 00 14 0f 0a 05 00 00 00 00 00 00 00 00 00 05 0a 0f 00 00 00 80 00 00 00 80 00 00 00 80 00 00 00 80 00 00 00 80 00 00 00 80 00 00 00 80 00 00 00 80 00 00 00 80 00 00 00 80 00 00 00 80 00 00 00 80 00 00 00 80 00 00 00 80 00 00 00 80 00 00 00 80 00 00 00 80 00 00 00 82 80 40 10 00 00 00 00 00 00 00 00 00 00 00 00 00 14 0f 0a 05 00 00 00 00 00 00 00 00 00 05 0a 0f 00 00 00 80 00 00 00 80 00 00 00 80 00 00 00 80 00 00 00 80 00 00 00 80 00 00 00 80 00 00 00 80 00 00 00 80 00 00 00 80 00 00 00 80 00 00 00 80 00 00 00 80 00 00 00 80 00 00 00 80 00 00 00 80 00 00 00 80 00 00 00 82 80 40 10 00 00 00 00 00 00 00 00 00 00 00 00 00 14 0f 0a 05 00 00 00 00 00 00 00 00 00 05 0a 0f 00 00 00 80 00 00 00 80 00 00 00 80 00 00 00 80 00 00 00 80 00 00 00 80 00 00 00 80 00 00 00 80 00 00 00 80 00 00 00 80 00 00 00 80 00 00 00 80 00 00 00 80 00 00 00 80 00 00 00 80 00 00 00 80 00 00 00 80 00 00 00 80 80 40 10 00 00 00 00 00 00 00 00 00 00 00 00 00 14 0f 0a 05 00 00 00 00 00 00 00 00 00 05 0a 0f 00 00 00 80 00 00 00 80 00 00 00 80 00 00 00 80 00 00 00 80 00 00 00 80 00 00 00 80 00 00 00 80 00 00 00 80 00 00 00 80 00 00 00 80 00 00 00 80 00 00 00 80 00 00 00 80 00 00 00 80 00 00 00 80 00 00 00 80 00 00 00 80 80 40 10 00 00 00 00 00 00 00 00 00 00 00 00 00 14 0f 0a 05 00 00 00 00 00 00 00 00 00 05 0a 0f 00 00 00 80 00 00 00 80 00 00 00 80 00 00 00 80 00 00 00 80 00 00 00 80 00 00 00 80 00 00 00 80 00 00 00 80 00 00 00 80 00 00 00 80 00 00 00 80 00 00 00 80 00 00 00 80 00 00 00 80 00 00 00 80 00 00 00 80 00 00 00 80 80 40 10 00 00 00 00 00 00 00 00 00 00 00 00 00 14 0f 0a 05 00 00 00 00 00 00 00 00 00 05 0a 0f 00 00 00 80 00 00 00 80 00 00 00 80 00 00 00 80 00 00 00 80 00 00 00 80 00 00 00 80 00 00 00 80 00 00 00 80 00 00 00 80 00 00 00 80 00 00 00 80 00 00 00 80 00 00 00 80 00 00 00 80 00 00 00 80 00 00 00 80 00 00 00 80 80 40 10 00 00 00 00 00 00 00 00 00 00 00 00 00 14 0f 0a 05 00 00 00 00 00 00 00 00 00 05 0a 0f 00 00 00 80 00 00 00 80 00 00 00 80 00 00 00 80 00 00 00 80 00 00 00 80 00 00 00 80 00 00 00 80 00 00 00 80 00 00 00 80 00 00 00 80 00 00 00 80 00 00 00 80 00 00 00 80 00 00 00 80 00 00 00 80 00 00 00 80 00 00 00 80 80 40 10 00 00 00 00 00 00 00 00 00 00 00 00 00 14 0f 0a 05 00 00 00 00 00 00 00 00 00 05 0a 0f 00 00 00 80 00 00 00 80 00 00 00 80 00 00 00 80 00 00 00 80 00 00 00 80 00 00 00 80 00 00 00 80 00 00 00 80 00 00 00 80 00 00 00 80 00 00 00 80 00 00 00 80 00 00 00 80 00 00 00 80 00 00 00 80 00 00 00 80 00 00 00 80 80 40 10 00 00 00 00 00 00 00 00 00 00 00 00 00 14 0f 0a 05 00 00 00 00 00 00 00 00 00 05 0a 0f 00 00 00 80 00 00 00 80 00 00 00 80 00 00 00 80 00 00 00 80 00 00 00 80 00 00 00 80 00 00 00 80 00 00 00 80 00 00 00 80 00 00 00 80 00 00 00 80 00 00 00 80 00 00 00 80 00 00 00 80 00 00 00 80 00 00 00 80 00 00 00 80 80 40 10 00 00 00 00 00 00 00 00 00 00 00 00 00 14 0f 0a 05 00 00 00 00 00 00 00 00 00 05 0a 0f 00 00 00 80 00 00 00 80 00 00 00 80 00 00 00 80 00 00 00 80 00 00 00 80 00 00 00 80 00 00 00 80 00 00 00 80 00 00 00 80 00 00 00 80 00 00 00 80 00 00 00 80 00 00 00 80 00 00 00 80 00 00 00 80 00 00 00 80 00 00 00 80 80 40 10 00 00 00 00 00 00 00 00 00 00 00 00 00 14 0f 0a 05 00 00 00 00 00 00 00 00 00 05 0a 0f 00 00 00 80 00 00 00 80 00 00 00 80 00 00 00 80 00 00 00 80 00 00 00 80 00 00 00 80 00 00 00 80 00 00 00 80 00 00 00 80 00 00 00 80 00 00 00 80 00 00 00 80 00 00 00 80 00 00 00 80 00 00 00 80 00 00 00 80 00 00 00 80 80 40 10 00 00 00 00 00 00 00 00 00 00 00 00 00 14 0f 0a 05 00 00 00 00 00 00 00 00 00 05 0a 0f 00 00 00 80 00 00 00 80 00 00 00 80 00 00 00 80 00 00 00 80 00 00 00 80 00 00 00 80 00 00 00 80 00 00 00 80 00 00 00 80 00 00 00 80 00 00 00 80 00 00 00 80 00 00 00 80 00 00 00 80 00 00 00 80 00 00 00 80 00 00 00];
		};
		iq_contrast {
			size = [b0 00 00 00];
			data = [00 00 00 00 80 00 00 00 00 00 00 00 00 00 80 0a 0a 0a 0a 0a 0a 0a 0a 0a 80 0a 0a 0a 0a 0a 0a 0a 0a 0a 80 0a 0a 0a 0a 0a 0a 0a 0a 0a 7b 14 14 14 14 14 14 14 14 14 78 14 14 14 14 14 14 14 14 14 78 14 14 14 14 14 14 14 14 14 78 0a 0a 0a 0a 0a 0a 0a 0a 0a 78 0a 0a 0a 0a 0a 0a 0a 0a 0a 78 0a 0a 0a 0a 0a 0a 0a 0a 0a 78 0a 0a 0a 0a 0a 0a 0a 0a 0a 78 0a 0a 0a 0a 0a 0a 0a 0a 0a 78 0a 0a 0a 0a 0a 0a 0a 0a 0a 74 0a 0a 0a 0a 0a 0a 0a 0a 0a 74 0a 0a 0a 0a 0a 0a 0a 0a 0a 74 0a 0a 0a 0a 0a 0a 0a 0a 0a 74 0a 0a 0a 0a 0a 0a 0a 0a 0a 00 00];
		};
		iq_edge {
			size = [14 05 00 00];
			data = [01 00 00 00 00 00 00 00 80 00 00 00 40 00 00 00 37 67 8e b1 d1 ee ff ff ff ff db c1 ab 97 8e 8a 20 2d 35 40 40 40 40 40 40 40 40 40 40 34 2c 26 80 80 80 80 80 80 80 80 80 80 80 80 80 80 80 80 80 80 80 80 80 80 80 80 40 00 00 00 80 00 00 00 80 00 00 00 08 00 00 00 00 00 00 00 00 00 00 00 10 00 00 00 28 00 00 00 f0 00 00 00 00 01 00 00 00 01 00 00 00 00 00 00 80 00 00 00 00 00 00 00 02 00 00 00 00 00 00 00 00 02 00 00 00 00 00 00 05 00 00 00 64 00 00 00 64 00 00 00 10 00 00 00 10 00 00 00 00 00 00 00 10 00 00 00 3c 00 00 00 78 00 00 00 00 01 00 00 00 01 00 00 00 00 00 00 50 00 00 00 02 00 00 00 04 00 00 00 00 00 00 00 00 02 00 00 00 00 00 00 05 00 00 00 64 00 00 00 64 00 00 00 10 00 00 00 10 00 00 00 00 00 00 00 10 00 00 00 3c 00 00 00 78 00 00 00 00 01 00 00 00 01 00 00 00 00 00 00 50 00 00 00 02 00 00 00 04 00 00 00 00 00 00 00 00 02 00 00 00 00 00 00 05 00 00 00 64 00 00 00 64 00 00 00 10 00 00 00 10 00 00 00 00 00 00 00 10 00 00 00 46 00 00 00 78 00 00 00 00 01 00 00 00 01 00 00 00 00 00 00 50 00 00 00 02 00 00 00 04 00 00 00 00 00 00 00 00 02 00 00 00 00 00 00 05 00 00 00 64 00 00 00 8c 00 00 00 0c 00 00 00 08 00 00 00 00 00 00 00 0c 00 00 00 50 00 00 00 96 00 00 00 00 01 00 00 00 01 00 00 00 00 00 00 50 00 00 00 02 00 00 00 04 00 00 00 00 00 00 00 00 02 00 00 00 00 00 00 05 00 00 00 64 00 00 00 8c 00 00 00 08 00 00 00 08 00 00 00 00 00 00 00 08 00 00 00 3c 00 00 00 96 00 00 00 00 01 00 00 00 01 00 00 00 00 00 00 50 00 00 00 02 00 00 00 04 00 00 00 00 00 00 00 00 02 00 00 00 00 00 00 05 00 00 00 64 00 00 00 8c 00 00 00 04 00 00 00 04 00 00 00 00 00 00 00 08 00 00 00 78 00 00 00 04 01 00 00 00 01 00 00 00 01 00 00 00 00 00 00 50 00 00 00 03 00 00 00 04 00 00 00 00 00 00 00 00 02 00 00 00 00 00 00 05 00 00 00 4b 00 00 00 32 00 00 00 02 00 00 00 00 00 00 00 00 00 00 00 04 00 00 00 96 00 00 00 04 01 00 00 00 01 00 00 00 01 00 00 00 00 00 00 50 00 00 00 03 00 00 00 04 00 00 00 00 00 00 00 00 02 00 00 00 00 00 00 05 00 00 00 46 00 00 00 2d 00 00 00 02 00 00 00 00 00 00 00 00 00 00 00 04 00 00 00 96 00 00 00 2c 01 00 00 00 01 00 00 00 01 00 00 00 00 00 00 50 00 00 00 03 00 00 00 04 00 00 00 00 00 00 00 00 02 00 00 00 00 00 00 05 00 00 00 46 00 00 00 28 00 00 00 00 00 00 00 00 00 00 00 00 00 00 00 04 00 00 00 96 00 00 00 2c 01 00 00 00 01 00 00 00 01 00 00 00 00 00 00 80 00 00 00 03 00 00 00 04 00 00 00 00 00 00 00 00 02 00 00 00 00 00 00 05 00 00 00 4b 00 00 00 80 00 00 00 00 00 00 00 00 00 00 00 00 00 00 00 04 00 00 00 96 00 00 00 2c 01 00 00 00 01 00 00 00 01 00 00 00 00 00 00 80 00 00 00 03 00 00 00 04 00 00 00 00 00 00 00 00 02 00 00 00 00 00 00 05 00 00 00 4b 00 00 00 6e 00 00 00 00 00 00 00 00 00 00 00 00 00 00 00 04 00 00 00 4d 00 00 00 09 01 00 00 00 01 00 00 00 01 00 00 00 00 00 00 80 00 00 00 03 00 00 00 02 00 00 00 00 00 00 00 00 02 00 00 00 00 00 00 05 00 00 00 4b 00 00 00 50 00 00 00 00 00 00 00 00 00 00 00 00 00 00 00 04 00 00 00 4d 00 00 00 09 01 00 00 00 01 00 00 00 01 00 00 00 00 00 00 80 00 00 00 04 00 00 00 02 00 00 00 00 00 00 00 00 02 00 00 00 00 00 00 05 00 00 00 3c 00 00 00 3c 00 00 00 00 00 00 00 00 00 00 00 00 00 00 00 04 00 00 00 93 02 00 00 f5 02 00 00 00 01 00 00 00 01 00 00 00 00 00 00 80 00 00 00 05 00 00 00 02 00 00 00 00 00 00 00 00 02 00 00 00 00 00 00 05 00 00 00 3c 00 00 00 3c 00 00 00 00 00 00 00 00 00 00 00 00 00 00 00 04 00 00 00 93 02 00 00 f5 02 00 00 00 01 00 00 00 01 00 00 00 00 00 00 80 00 00 00 05 00 00 00 02 00 00 00 00 00 00 00 00 02 00 00 00 00 00 00 05 00 00 00 3c 00 00 00 3c 00 00 00 00 00 00 00 00 00 00 00 00 00 00 00 04 00 00 00 93 02 00 00 f5 02 00 00 00 01 00 00 00 01 00 00 00 00 00 00 80 00 00 00 05 00 00 00 02 00 00 00 00 00 00 00 00 02 00 00 00 00 00 00 05 00 00 00 3c 00 00 00 3c 00 00 00 00 00 00 00 00 00 00 00 00 00 00 00 04 00 00 00 93 02 00 00 f5 02 00 00 00 01 00 00 00 01 00 00 00 00 00 00 80 00 00 00 05 00 00 00 02 00 00 00 00 00 00 00 00 02 00 00 00 00 00 00 05 00 00 00];
		};
		iq_3dnr {
			size = [50 1e 00 00];
			data = [01 00 00 00 00 00 00 00 40 00 00 00 40 00 00 00 00 00 00 00 80 00 00 00 80 00 00 00 80 00 00 00 c8 00 00 00 c8 00 00 00 04 00 00 00 04 00 00 00 03 00 00 00 04 00 00 00 04 00 00 00 04 00 00 00 04 00 00 00 04 00 00 00 05 00 00 00 05 00 00 00 06 00 00 00 06 00 00 00 07 00 00 00 07 00 00 00 08 00 00 00 08 00 00 00 80 00 00 00 04 00 00 00 00 00 00 00 00 00 00 00 00 00 00 00 00 00 00 00 00 00 00 00 00 00 00 00 00 00 00 00 00 00 00 00 00 00 00 00 00 00 00 00 00 00 00 00 00 00 00 00 00 00 00 00 00 00 00 00 00 00 00 00 00 00 00 00 00 00 00 00 00 00 00 00 00 00 00 00 00 00 00 00 00 00 00 00 00 00 00 00 00 00 00 00 00 00 00 00 00 00 00 00 00 00 00 00 00 00 00 00 00 00 00 00 00 00 00 00 00 00 00 00 00 00 00 00 00 00 00 00 08 00 00 00 10 00 00 00 04 00 00 00 b4 00 00 00 e6 00 00 00 06 00 00 00 01 00 00 00 01 00 00 00 10 00 00 00 20 00 00 00 30 00 00 00 40 00 00 00 80 00 00 00 40 00 00 00 00 01 00 00 00 01 00 00 10 00 00 00 10 00 00 00 10 00 00 00 10 00 00 00 10 00 00 00 10 00 00 00 10 00 00 00 10 00 00 00 10 00 00 00 10 00 00 00 10 00 00 00 10 00 00 00 08 00 00 00 10 00 00 00 40 00 00 00 40 00 00 00 10 00 00 00 08 00 00 00 08 00 00 00 10 00 00 00 18 00 00 00 20 00 00 00 00 00 00 00 06 00 00 00 0c 00 00 00 18 00 00 00 28 00 00 00 4c 00 00 00 60 00 00 00 70 00 00 00 00 00 00 00 06 00 00 00 0c 00 00 00 18 00 00 00 28 00 00 00 4c 00 00 00 60 00 00 00 70 00 00 00 80 00 00 00 40 00 00 00 40 00 00 00 40 00 00 00 00 00 00 00 64 00 00 00 64 00 00 00 64 00 00 00 c8 00 00 00 c8 00 00 00 04 00 00 00 04 00 00 00 03 00 00 00 04 00 00 00 04 00 00 00 04 00 00 00 04 00 00 00 04 00 00 00 04 00 00 00 04 00 00 00 05 00 00 00 06 00 00 00 06 00 00 00 07 00 00 00 07 00 00 00 08 00 00 00 ff 00 00 00 08 00 00 00 c8 00 00 00 dc 00 00 00 dc 00 00 00 c8 00 00 00 c8 00 00 00 c8 00 00 00 c8 00 00 00 c8 00 00 00 06 00 00 00 06 00 00 00 06 00 00 00 06 00 00 00 05 00 00 00 05 00 00 00 05 00 00 00 05 00 00 00 96 00 00 00 78 00 00 00 5a 00 00 00 5a 00 00 00 50 00 00 00 50 00 00 00 50 00 00 00 50 00 00 00 23 00 00 00 23 00 00 00 23 00 00 00 19 00 00 00 19 00 00 00 19 00 00 00 19 00 00 00 19 00 00 00 08 00 00 00 10 00 00 00 05 00 00 00 80 00 00 00 e6 00 00 00 06 00 00 00 01 00 00 00 01 00 00 00 10 00 00 00 20 00 00 00 30 00 00 00 40 00 00 00 80 00 00 00 40 00 00 00 f4 01 00 00 f4 01 00 00 10 00 00 00 10 00 00 00 10 00 00 00 10 00 00 00 10 00 00 00 10 00 00 00 10 00 00 00 10 00 00 00 10 00 00 00 10 00 00 00 10 00 00 00 10 00 00 00 00 00 00 00 10 00 00 00 20 00 00 00 10 00 00 00 00 00 00 00 00 00 00 00 02 00 00 00 04 00 00 00 08 00 00 00 0c 00 00 00 00 00 00 00 10 00 00 00 20 00 00 00 30 00 00 00 40 00 00 00 50 00 00 00 60 00 00 00 70 00 00 00 00 00 00 00 10 00 00 00 20 00 00 00 30 00 00 00 40 00 00 00 50 00 00 00 60 00 00 00 70 00 00 00 80 00 00 00 40 00 00 00 64 00 00 00 64 00 00 00 00 00 00 00 c8 00 00 00 c8 00 00 00 c8 00 00 00 5e 01 00 00 5e 01 00 00 04 00 00 00 04 00 00 00 03 00 00 00 04 00 00 00 04 00 00 00 04 00 00 00 04 00 00 00 04 00 00 00 04 00 00 00 04 00 00 00 05 00 00 00 06 00 00 00 06 00 00 00 07 00 00 00 07 00 00 00 08 00 00 00 ff 00 00 00 07 00 00 00 c8 00 00 00 dc 00 00 00 dc 00 00 00 c8 00 00 00 c8 00 00 00 c8 00 00 00 c8 00 00 00 c8 00 00 00 06 00 00 00 06 00 00 00 07 00 00 00 08 00 00 00 06 00 00 00 06 00 00 00 06 00 00 00 06 00 00 00 fa 00 00 00 fa 00 00 00 a0 00 00 00 96 00 00 00 6e 00 00 00 6e 00 00 00 6e 00 00 00 6e 00 00 00 2d 00 00 00 2d 00 00 00 28 00 00 00 1e 00 00 00 19 00 00 00 19 00 00 00 19 00 00 00 19 00 00 00 08 00 00 00 10 00 00 00 05 00 00 00 80 00 00 00 e6 00 00 00 06 00 00 00 01 00 00 00 01 00 00 00 10 00 00 00 20 00 00 00 30 00 00 00 40 00 00 00 80 00 00 00 40 00 00 00 f4 01 00 00 f4 01 00 00 10 00 00 00 10 00 00 00 10 00 00 00 10 00 00 00 10 00 00 00 10 00 00 00 10 00 00 00 10 00 00 00 10 00 00 00 10 00 00 00 10 00 00 00 10 00 00 00 00 00 00 00 10 00 00 00 20 00 00 00 20 00 00 00 00 00 00 00 00 00 00 00 02 00 00 00 04 00 00 00 08 00 00 00 0c 00 00 00 00 00 00 00 10 00 00 00 20 00 00 00 30 00 00 00 40 00 00 00 50 00 00 00 60 00 00 00 70 00 00 00 00 00 00 00 10 00 00 00 20 00 00 00 30 00 00 00 40 00 00 00 50 00 00 00 60 00 00 00 70 00 00 00 80 00 00 00 40 00 00 00 96 00 00 00 96 00 00 00 00 00 00 00 2c 01 00 00 2c 01 00 00 2c 01 00 00 f4 01 00 00 f4 01 00 00 04 00 00 00 04 00 00 00 03 00 00 00 04 00 00 00 04 00 00 00 04 00 00 00 04 00 00 00 04 00 00 00 04 00 00 00 04 00 00 00 05 00 00 00 06 00 00 00 06 00 00 00 07 00 00 00 07 00 00 00 08 00 00 00 dc 00 00 00 07 00 00 00 7c 01 00 00 90 01 00 00 90 01 00 00 7c 01 00 00 7c 01 00 00 7c 01 00 00 7c 01 00 00 7c 01 00 00 06 00 00 00 07 00 00 00 08 00 00 00 09 00 00 00 07 00 00 00 07 00 00 00 07 00 00 00 07 00 00 00 2c 01 00 00 2c 01 00 00 fa 00 00 00 c8 00 00 00 8c 00 00 00 8c 00 00 00 8c 00 00 00 8c 00 00 00 32 00 00 00 32 00 00 00 2d 00 00 00 2d 00 00 00 1e 00 00 00 19 00 00 00 19 00 00 00 19 00 00 00 08 00 00 00 10 00 00 00 05 00 00 00 80 00 00 00 e6 00 00 00 06 00 00 00 01 00 00 00 01 00 00 00 10 00 00 00 20 00 00 00 30 00 00 00 40 00 00 00 80 00 00 00 40 00 00 00 f4 01 00 00 e8 03 00 00 10 00 00 00 10 00 00 00 10 00 00 00 10 00 00 00 10 00 00 00 10 00 00 00 10 00 00 00 10 00 00 00 10 00 00 00 10 00 00 00 10 00 00 00 10 00 00 00 00 00 00 00 10 00 00 00 20 00 00 00 20 00 00 00 10 00 00 00 00 00 00 00 02 00 00 00 04 00 00 00 08 00 00 00 0c 00 00 00 00 00 00 00 10 00 00 00 20 00 00 00 30 00 00 00 40 00 00 00 50 00 00 00 60 00 00 00 70 00 00 00 00 00 00 00 10 00 00 00 20 00 00 00 30 00 00 00 40 00 00 00 50 00 00 00 60 00 00 00 70 00 00 00 80 00 00 00 40 00 00 00 96 00 00 00 96 00 00 00 00 00 00 00 2c 01 00 00 2c 01 00 00 2c 01 00 00 f4 01 00 00 f4 01 00 00 04 00 00 00 04 00 00 00 03 00 00 00 04 00 00 00 04 00 00 00 04 00 00 00 04 00 00 00 04 00 00 00 04 00 00 00 04 00 00 00 05 00 00 00 06 00 00 00 06 00 00 00 07 00 00 00 07 00 00 00 08 00 00 00 dc 00 00 00 06 00 00 00 30 02 00 00 80 02 00 00 80 02 00 00 30 02 00 00 30 02 00 00 30 02 00 00 08 00 00 00 30 02 00 00 07 00 00 00 08 00 00 00 09 00 00 00 0a 00 00 00 08 00 00 00 08 00 00 00 08 00 00 00 08 00 00 00 2c 01 00 00 2c 01 00 00 fa 00 00 00 fa 00 00 00 aa 00 00 00 aa 00 00 00 aa 00 00 00 aa 00 00 00 32 00 00 00 32 00 00 00 2d 00 00 00 2d 00 00 00 1e 00 00 00 1e 00 00 00 1e 00 00 00 1e 00 00 00 08 00 00 00 10 00 00 00 05 00 00 00 80 00 00 00 e6 00 00 00 06 00 00 00 01 00 00 00 01 00 00 00 10 00 00 00 20 00 00 00 30 00 00 00 40 00 00 00 80 00 00 00 40 00 00 00 f4 01 00 00 e8 03 00 00 10 00 00 00 10 00 00 00 10 00 00 00 10 00 00 00 10 00 00 00 10 00 00 00 10 00 00 00 10 00 00 00 10 00 00 00 10 00 00 00 10 00 00 00 10 00 00 00 00 00 00 00 10 00 00 00 20 00 00 00 40 00 00 00 20 00 00 00 00 00 00 00 08 00 00 00 10 00 00 00 18 00 00 00 1c 00 00 00 00 00 00 00 10 00 00 00 20 00 00 00 30 00 00 00 40 00 00 00 50 00 00 00 60 00 00 00 70 00 00 00 00 00 00 00 10 00 00 00 20 00 00 00 30 00 00 00 40 00 00 00 50 00 00 00 60 00 00 00 70 00 00 00 80 00 00 00 40 00 00 00 96 00 00 00 96 00 00 00 00 00 00 00 2c 01 00 00 2c 01 00 00 2c 01 00 00 f4 01 00 00 f4 01 00 00 04 00 00 00 04 00 00 00 03 00 00 00 04 00 00 00 04 00 00 00 04 00 00 00 04 00 00 00 04 00 00 00 04 00 00 00 04 00 00 00 05 00 00 00 06 00 00 00 06 00 00 00 07 00 00 00 07 00 00 00 08 00 00 00 dc 00 00 00 06 00 00 00 58 02 00 00 20 03 00 00 20 03 00 00 58 02 00 00 58 02 00 00 58 02 00 00 58 02 00 00 58 02 00 00 09 00 00 00 0a 00 00 00 0b 00 00 00 0b 00 00 00 0a 00 00 00 0a 00 00 00 0a 00 00 00 0a 00 00 00 90 01 00 00 90 01 00 00 2c 01 00 00 fa 00 00 00 c8 00 00 00 c8 00 00 00 c8 00 00 00 c8 00 00 00 3c 00 00 00 3c 00 00 00 32 00 00 00 32 00 00 00 28 00 00 00 1e 00 00 00 1e 00 00 00 1e 00 00 00 08 00 00 00 10 00 00 00 05 00 00 00 80 00 00 00 e6 00 00 00 06 00 00 00 01 00 00 00 01 00 00 00 10 00 00 00 20 00 00 00 30 00 00 00 40 00 00 00 80 00 00 00 40 00 00 00 e8 03 00 00 dc 05 00 00 10 00 00 00 10 00 00 00 10 00 00 00 10 00 00 00 10 00 00 00 10 00 00 00 10 00 00 00 10 00 00 00 10 00 00 00 10 00 00 00 10 00 00 00 10 00 00 00 00 00 00 00 10 00 00 00 20 00 00 00 40 00 00 00 20 00 00 00 00 00 00 00 08 00 00 00 10 00 00 00 18 00 00 00 1c 00 00 00 00 00 00 00 0b 00 00 00 13 00 00 00 1b 00 00 00 23 00 00 00 2b 00 00 00 31 00 00 00 3a 00 00 00 00 00 00 00 0d 00 00 00 15 00 00 00 1e 00 00 00 23 00 00 00 29 00 00 00 31 00 00 00 3c 00 00 00 80 00 00 00 40 00 00 00 fa 00 00 00 fa 00 00 00 00 00 00 00 f4 01 00 00 f4 01 00 00 f4 01 00 00 bc 02 00 00 bc 02 00 00 04 00 00 00 04 00 00 00 03 00 00 00 04 00 00 00 04 00 00 00 04 00 00 00 04 00 00 00 04 00 00 00 06 00 00 00 06 00 00 00 06 00 00 00 06 00 00 00 06 00 00 00 07 00 00 00 07 00 00 00 08 00 00 00 a0 00 00 00 06 00 00 00 f4 01 00 00 f4 01 00 00 f4 01 00 00 f4 01 00 00 58 02 00 00 84 03 00 00 84 03 00 00 84 03 00 00 09 00 00 00 0a 00 00 00 0b 00 00 00 0b 00 00 00 0a 00 00 00 0a 00 00 00 0a 00 00 00 0a 00 00 00 f4 01 00 00 f4 01 00 00 90 01 00 00 fa 00 00 00 dc 00 00 00 dc 00 00 00 dc 00 00 00 dc 00 00 00 41 00 00 00 41 00 00 00 41 00 00 00 3c 00 00 00 3c 00 00 00 32 00 00 00 32 00 00 00 32 00 00 00 08 00 00 00 10 00 00 00 03 00 00 00 b4 00 00 00 e6 00 00 00 03 00 00 00 01 00 00 00 01 00 00 00 10 00 00 00 20 00 00 00 40 00 00 00 50 00 00 00 80 00 00 00 40 00 00 00 e8 03 00 00 e8 03 00 00 10 00 00 00 10 00 00 00 20 00 00 00 20 00 00 00 10 00 00 00 10 00 00 00 10 00 00 00 10 00 00 00 10 00 00 00 10 00 00 00 10 00 00 00 10 00 00 00 00 00 00 00 50 00 00 00 64 00 00 00 40 00 00 00 20 00 00 00 00 00 00 00 08 00 00 00 10 00 00 00 18 00 00 00 1c 00 00 00 00 00 00 00 0b 00 00 00 13 00 00 00 1b 00 00 00 23 00 00 00 2b 00 00 00 31 00 00 00 3a 00 00 00 00 00 00 00 0d 00 00 00 15 00 00 00 1e 00 00 00 23 00 00 00 29 00 00 00 31 00 00 00 3c 00 00 00 80 00 00 00 40 00 00 00 fa 00 00 00 fa 00 00 00 00 00 00 00 f4 01 00 00 f4 01 00 00 f4 01 00 00 bc 02 00 00 bc 02 00 00 04 00 00 00 04 00 00 00 03 00 00 00 04 00 00 00 04 00 00 00 04 00 00 00 04 00 00 00 04 00 00 00 04 00 00 00 05 00 00 00 05 00 00 00 05 00 00 00 06 00 00 00 07 00 00 00 07 00 00 00 08 00 00 00 8c 00 00 00 05 00 00 00 f4 01 00 00 f4 01 00 00 f4 01 00 00 f4 01 00 00 58 02 00 00 84 03 00 00 84 03 00 00 84 03 00 00 0a 00 00 00 0b 00 00 00 0c 00 00 00 0c 00 00 00 0b 00 00 00 0b 00 00 00 0b 00 00 00 0b 00 00 00 1c 02 00 00 1c 02 00 00 b8 01 00 00 22 01 00 00 22 01 00 00 36 01 00 00 36 01 00 00 36 01 00 00 41 00 00 00 41 00 00 00 41 00 00 00 3c 00 00 00 3c 00 00 00 32 00 00 00 32 00 00 00 32 00 00 00 08 00 00 00 10 00 00 00 03 00 00 00 b4 00 00 00 e6 00 00 00 03 00 00 00 01 00 00 00 01 00 00 00 20 00 00 00 30 00 00 00 50 00 00 00 64 00 00 00 80 00 00 00 40 00 00 00 e8 03 00 00 e8 03 00 00 10 00 00 00 10 00 00 00 20 00 00 00 20 00 00 00 10 00 00 00 10 00 00 00 10 00 00 00 10 00 00 00 10 00 00 00 10 00 00 00 10 00 00 00 10 00 00 00 00 00 00 00 40 00 00 00 80 00 00 00 40 00 00 00 20 00 00 00 00 00 00 00 08 00 00 00 10 00 00 00 18 00 00 00 1c 00 00 00 00 00 00 00 0a 00 00 00 11 00 00 00 18 00 00 00 23 00 00 00 2a 00 00 00 32 00 00 00 3a 00 00 00 00 00 00 00 0a 00 00 00 12 00 00 00 16 00 00 00 19 00 00 00 1e 00 00 00 24 00 00 00 2a 00 00 00 80 00 00 00 40 00 00 00 90 01 00 00 90 01 00 00 00 00 00 00 58 02 00 00 58 02 00 00 58 02 00 00 84 03 00 00 84 03 00 00 04 00 00 00 04 00 00 00 03 00 00 00 04 00 00 00 04 00 00 00 04 00 00 00 04 00 00 00 04 00 00 00 04 00 00 00 05 00 00 00 05 00 00 00 05 00 00 00 06 00 00 00 07 00 00 00 07 00 00 00 08 00 00 00 8c 00 00 00 05 00 00 00 f4 01 00 00 f4 01 00 00 f4 01 00 00 f4 01 00 00 58 02 00 00 84 03 00 00 84 03 00 00 84 03 00 00 0c 00 00 00 0d 00 00 00 0e 00 00 00 0e 00 00 00 0d 00 00 00 0d 00 00 00 0d 00 00 00 0d 00 00 00 bc 02 00 00 bc 02 00 00 58 02 00 00 f4 01 00 00 90 01 00 00 86 01 00 00 86 01 00 00 86 01 00 00 50 00 00 00 50 00 00 00 4b 00 00 00 46 00 00 00 46 00 00 00 3c 00 00 00 3c 00 00 00 3c 00 00 00 08 00 00 00 10 00 00 00 03 00 00 00 b4 00 00 00 e6 00 00 00 03 00 00 00 01 00 00 00 01 00 00 00 20 00 00 00 30 00 00 00 50 00 00 00 64 00 00 00 80 00 00 00 40 00 00 00 e8 03 00 00 dc 05 00 00 10 00 00 00 10 00 00 00 20 00 00 00 20 00 00 00 10 00 00 00 10 00 00 00 10 00 00 00 10 00 00 00 10 00 00 00 10 00 00 00 10 00 00 00 10 00 00 00 00 00 00 00 40 00 00 00 80 00 00 00 40 00 00 00 20 00 00 00 00 00 00 00 08 00 00 00 10 00 00 00 18 00 00 00 1c 00 00 00 00 00 00 00 0a 00 00 00 11 00 00 00 18 00 00 00 23 00 00 00 2a 00 00 00 32 00 00 00 3a 00 00 00 00 00 00 00 0a 00 00 00 12 00 00 00 16 00 00 00 19 00 00 00 1e 00 00 00 24 00 00 00 2a 00 00 00 80 00 00 00 40 00 00 00 64 00 00 00 64 00 00 00 00 00 00 00 c8 00 00 00 c8 00 00 00 c8 00 00 00 90 01 00 00 90 01 00 00 04 00 00 00 04 00 00 00 03 00 00 00 04 00 00 00 04 00 00 00 04 00 00 00 04 00 00 00 04 00 00 00 04 00 00 00 05 00 00 00 05 00 00 00 05 00 00 00 06 00 00 00 07 00 00 00 07 00 00 00 08 00 00 00 8c 00 00 00 05 00 00 00 f4 01 00 00 f4 01 00 00 f4 01 00 00 f4 01 00 00 58 02 00 00 84 03 00 00 84 03 00 00 84 03 00 00 0b 00 00 00 0f 00 00 00 0f 00 00 00 0e 00 00 00 0e 00 00 00 0c 00 00 00 0c 00 00 00 0c 00 00 00 9a 01 00 00 9a 01 00 00 9a 01 00 00 9a 01 00 00 9a 01 00 00 ae 01 00 00 ae 01 00 00 ae 01 00 00 3c 00 00 00 3c 00 00 00 3c 00 00 00 3c 00 00 00 3c 00 00 00 32 00 00 00 32 00 00 00 32 00 00 00 08 00 00 00 10 00 00 00 03 00 00 00 b4 00 00 00 e6 00 00 00 03 00 00 00 01 00 00 00 01 00 00 00 20 00 00 00 30 00 00 00 50 00 00 00 64 00 00 00 80 00 00 00 40 00 00 00 dc 05 00 00 dc 05 00 00 10 00 00 00 10 00 00 00 20 00 00 00 20 00 00 00 10 00 00 00 10 00 00 00 10 00 00 00 10 00 00 00 10 00 00 00 10 00 00 00 10 00 00 00 10 00 00 00 00 00 00 00 40 00 00 00 80 00 00 00 40 00 00 00 20 00 00 00 00 00 00 00 08 00 00 00 10 00 00 00 18 00 00 00 1c 00 00 00 00 00 00 00 02 00 00 00 0e 00 00 00 15 00 00 00 20 00 00 00 24 00 00 00 2f 00 00 00 3a 00 00 00 00 00 00 00 03 00 00 00 0b 00 00 00 0e 00 00 00 16 00 00 00 18 00 00 00 20 00 00 00 26 00 00 00 80 00 00 00 40 00 00 00 64 00 00 00 64 00 00 00 00 00 00 00 c8 00 00 00 c8 00 00 00 c8 00 00 00 90 01 00 00 90 01 00 00 04 00 00 00 04 00 00 00 03 00 00 00 04 00 00 00 04 00 00 00 04 00 00 00 04 00 00 00 04 00 00 00 04 00 00 00 05 00 00 00 05 00 00 00 05 00 00 00 06 00 00 00 07 00 00 00 07 00 00 00 08 00 00 00 8c 00 00 00 05 00 00 00 f4 01 00 00 f4 01 00 00 f4 01 00 00 f4 01 00 00 58 02 00 00 84 03 00 00 84 03 00 00 84 03 00 00 0b 00 00 00 0f 00 00 00 0f 00 00 00 0e 00 00 00 0e 00 00 00 0c 00 00 00 0c 00 00 00 0c 00 00 00 9a 01 00 00 9a 01 00 00 9a 01 00 00 9a 01 00 00 9a 01 00 00 ae 01 00 00 ae 01 00 00 ae 01 00 00 3c 00 00 00 3c 00 00 00 3c 00 00 00 3c 00 00 00 3c 00 00 00 32 00 00 00 32 00 00 00 32 00 00 00 08 00 00 00 10 00 00 00 03 00 00 00 b4 00 00 00 e6 00 00 00 03 00 00 00 01 00 00 00 01 00 00 00 20 00 00 00 30 00 00 00 50 00 00 00 64 00 00 00 80 00 00 00 40 00 00 00 dc 05 00 00 dc 05 00 00 10 00 00 00 10 00 00 00 20 00 00 00 20 00 00 00 10 00 00 00 10 00 00 00 10 00 00 00 10 00 00 00 10 00 00 00 10 00 00 00 10 00 00 00 10 00 00 00 00 00 00 00 40 00 00 00 80 00 00 00 40 00 00 00 20 00 00 00 00 00 00 00 08 00 00 00 10 00 00 00 18 00 00 00 1c 00 00 00 00 00 00 00 02 00 00 00 0e 00 00 00 15 00 00 00 20 00 00 00 24 00 00 00 2f 00 00 00 3a 00 00 00 00 00 00 00 03 00 00 00 0b 00 00 00 0e 00 00 00 16 00 00 00 18 00 00 00 20 00 00 00 26 00 00 00 80 00 00 00 40 00 00 00 64 00 00 00 64 00 00 00 00 00 00 00 c8 00 00 00 c8 00 00 00 c8 00 00 00 90 01 00 00 90 01 00 00 04 00 00 00 04 00 00 00 03 00 00 00 04 00 00 00 04 00 00 00 04 00 00 00 04 00 00 00 04 00 00 00 04 00 00 00 05 00 00 00 05 00 00 00 05 00 00 00 06 00 00 00 07 00 00 00 07 00 00 00 08 00 00 00 8c 00 00 00 05 00 00 00 f4 01 00 00 f4 01 00 00 f4 01 00 00 f4 01 00 00 58 02 00 00 84 03 00 00 84 03 00 00 84 03 00 00 0b 00 00 00 0f 00 00 00 0f 00 00 00 0e 00 00 00 0e 00 00 00 0c 00 00 00 0c 00 00 00 0c 00 00 00 9a 01 00 00 9a 01 00 00 9a 01 00 00 9a 01 00 00 9a 01 00 00 ae 01 00 00 ae 01 00 00 ae 01 00 00 3c 00 00 00 3c 00 00 00 3c 00 00 00 3c 00 00 00 3c 00 00 00 32 00 00 00 32 00 00 00 32 00 00 00 08 00 00 00 10 00 00 00 03 00 00 00 b4 00 00 00 e6 00 00 00 03 00 00 00 01 00 00 00 01 00 00 00 20 00 00 00 30 00 00 00 50 00 00 00 64 00 00 00 80 00 00 00 40 00 00 00 dc 05 00 00 dc 05 00 00 10 00 00 00 10 00 00 00 20 00 00 00 20 00 00 00 10 00 00 00 10 00 00 00 10 00 00 00 10 00 00 00 10 00 00 00 10 00 00 00 10 00 00 00 10 00 00 00 00 00 00 00 40 00 00 00 80 00 00 00 40 00 00 00 20 00 00 00 00 00 00 00 08 00 00 00 10 00 00 00 18 00 00 00 1c 00 00 00 00 00 00 00 02 00 00 00 0e 00 00 00 15 00 00 00 20 00 00 00 24 00 00 00 2f 00 00 00 3a 00 00 00 00 00 00 00 03 00 00 00 0b 00 00 00 0e 00 00 00 16 00 00 00 18 00 00 00 20 00 00 00 26 00 00 00 80 00 00 00 40 00 00 00 64 00 00 00 64 00 00 00 00 00 00 00 c8 00 00 00 c8 00 00 00 c8 00 00 00 90 01 00 00 90 01 00 00 04 00 00 00 04 00 00 00 03 00 00 00 04 00 00 00 04 00 00 00 04 00 00 00 04 00 00 00 04 00 00 00 04 00 00 00 05 00 00 00 05 00 00 00 05 00 00 00 06 00 00 00 07 00 00 00 07 00 00 00 08 00 00 00 8c 00 00 00 05 00 00 00 f4 01 00 00 f4 01 00 00 f4 01 00 00 f4 01 00 00 58 02 00 00 84 03 00 00 84 03 00 00 84 03 00 00 0b 00 00 00 0f 00 00 00 0f 00 00 00 0e 00 00 00 0e 00 00 00 0c 00 00 00 0c 00 00 00 0c 00 00 00 9a 01 00 00 9a 01 00 00 9a 01 00 00 9a 01 00 00 9a 01 00 00 ae 01 00 00 ae 01 00 00 ae 01 00 00 3c 00 00 00 3c 00 00 00 3c 00 00 00 3c 00 00 00 3c 00 00 00 32 00 00 00 32 00 00 00 32 00 00 00 08 00 00 00 10 00 00 00 03 00 00 00 b4 00 00 00 e6 00 00 00 03 00 00 00 01 00 00 00 01 00 00 00 20 00 00 00 30 00 00 00 50 00 00 00 64 00 00 00 80 00 00 00 40 00 00 00 dc 05 00 00 dc 05 00 00 10 00 00 00 10 00 00 00 20 00 00 00 20 00 00 00 10 00 00 00 10 00 00 00 10 00 00 00 10 00 00 00 10 00 00 00 10 00 00 00 10 00 00 00 10 00 00 00 00 00 00 00 40 00 00 00 80 00 00 00 40 00 00 00 20 00 00 00 00 00 00 00 08 00 00 00 10 00 00 00 18 00 00 00 1c 00 00 00 00 00 00 00 02 00 00 00 0e 00 00 00 15 00 00 00 20 00 00 00 24 00 00 00 2f 00 00 00 3a 00 00 00 00 00 00 00 03 00 00 00 0b 00 00 00 0e 00 00 00 16 00 00 00 18 00 00 00 20 00 00 00 26 00 00 00 80 00 00 00 40 00 00 00 64 00 00 00 64 00 00 00 00 00 00 00 c8 00 00 00 c8 00 00 00 c8 00 00 00 90 01 00 00 90 01 00 00 04 00 00 00 04 00 00 00 03 00 00 00 04 00 00 00 04 00 00 00 04 00 00 00 04 00 00 00 04 00 00 00 04 00 00 00 05 00 00 00 05 00 00 00 05 00 00 00 06 00 00 00 07 00 00 00 07 00 00 00 08 00 00 00 8c 00 00 00 05 00 00 00 f4 01 00 00 f4 01 00 00 f4 01 00 00 f4 01 00 00 58 02 00 00 84 03 00 00 84 03 00 00 84 03 00 00 0b 00 00 00 0f 00 00 00 0f 00 00 00 0e 00 00 00 0e 00 00 00 0c 00 00 00 0c 00 00 00 0c 00 00 00 9a 01 00 00 9a 01 00 00 9a 01 00 00 9a 01 00 00 9a 01 00 00 ae 01 00 00 ae 01 00 00 ae 01 00 00 3c 00 00 00 3c 00 00 00 3c 00 00 00 3c 00 00 00 3c 00 00 00 32 00 00 00 32 00 00 00 32 00 00 00 08 00 00 00 10 00 00 00 03 00 00 00 b4 00 00 00 e6 00 00 00 03 00 00 00 01 00 00 00 01 00 00 00 20 00 00 00 30 00 00 00 50 00 00 00 64 00 00 00 80 00 00 00 40 00 00 00 dc 05 00 00 dc 05 00 00 10 00 00 00 10 00 00 00 20 00 00 00 20 00 00 00 10 00 00 00 10 00 00 00 10 00 00 00 10 00 00 00 10 00 00 00 10 00 00 00 10 00 00 00 10 00 00 00 00 00 00 00 40 00 00 00 80 00 00 00 40 00 00 00 20 00 00 00 00 00 00 00 08 00 00 00 10 00 00 00 18 00 00 00 1c 00 00 00 00 00 00 00 02 00 00 00 0e 00 00 00 15 00 00 00 20 00 00 00 24 00 00 00 2f 00 00 00 3a 00 00 00 00 00 00 00 03 00 00 00 0b 00 00 00 0e 00 00 00 16 00 00 00 18 00 00 00 20 00 00 00 26 00 00 00 80 00 00 00 40 00 00 00 64 00 00 00 64 00 00 00 00 00 00 00 c8 00 00 00 c8 00 00 00 c8 00 00 00 90 01 00 00 90 01 00 00 04 00 00 00 04 00 00 00 03 00 00 00 04 00 00 00 04 00 00 00 04 00 00 00 04 00 00 00 04 00 00 00 04 00 00 00 05 00 00 00 05 00 00 00 05 00 00 00 06 00 00 00 07 00 00 00 07 00 00 00 08 00 00 00 8c 00 00 00 05 00 00 00 f4 01 00 00 f4 01 00 00 f4 01 00 00 f4 01 00 00 58 02 00 00 84 03 00 00 84 03 00 00 84 03 00 00 0b 00 00 00 0f 00 00 00 0f 00 00 00 0e 00 00 00 0e 00 00 00 0c 00 00 00 0c 00 00 00 0c 00 00 00 9a 01 00 00 9a 01 00 00 9a 01 00 00 9a 01 00 00 9a 01 00 00 ae 01 00 00 ae 01 00 00 ae 01 00 00 3c 00 00 00 3c 00 00 00 3c 00 00 00 3c 00 00 00 3c 00 00 00 32 00 00 00 32 00 00 00 32 00 00 00 08 00 00 00 10 00 00 00 03 00 00 00 b4 00 00 00 e6 00 00 00 03 00 00 00 01 00 00 00 01 00 00 00 20 00 00 00 30 00 00 00 50 00 00 00 64 00 00 00 80 00 00 00 40 00 00 00 dc 05 00 00 dc 05 00 00 10 00 00 00 10 00 00 00 20 00 00 00 20 00 00 00 10 00 00 00 10 00 00 00 10 00 00 00 10 00 00 00 10 00 00 00 10 00 00 00 10 00 00 00 10 00 00 00 00 00 00 00 40 00 00 00 80 00 00 00 40 00 00 00 20 00 00 00 00 00 00 00 08 00 00 00 10 00 00 00 18 00 00 00 1c 00 00 00 00 00 00 00 02 00 00 00 0e 00 00 00 15 00 00 00 20 00 00 00 24 00 00 00 2f 00 00 00 3a 00 00 00 00 00 00 00 03 00 00 00 0b 00 00 00 0e 00 00 00 16 00 00 00 18 00 00 00 20 00 00 00 26 00 00 00 80 00 00 00 40 00 00 00 64 00 00 00 64 00 00 00 00 00 00 00 c8 00 00 00 c8 00 00 00 c8 00 00 00 90 01 00 00 90 01 00 00 04 00 00 00 04 00 00 00 03 00 00 00 04 00 00 00 04 00 00 00 04 00 00 00 04 00 00 00 04 00 00 00 04 00 00 00 05 00 00 00 05 00 00 00 05 00 00 00 06 00 00 00 07 00 00 00 07 00 00 00 08 00 00 00 8c 00 00 00 05 00 00 00 f4 01 00 00 f4 01 00 00 f4 01 00 00 f4 01 00 00 58 02 00 00 84 03 00 00 84 03 00 00 84 03 00 00 0b 00 00 00 0f 00 00 00 0f 00 00 00 0e 00 00 00 0e 00 00 00 0c 00 00 00 0c 00 00 00 0c 00 00 00 9a 01 00 00 9a 01 00 00 9a 01 00 00 9a 01 00 00 9a 01 00 00 ae 01 00 00 ae 01 00 00 ae 01 00 00 3c 00 00 00 3c 00 00 00 3c 00 00 00 3c 00 00 00 3c 00 00 00 32 00 00 00 32 00 00 00 32 00 00 00 08 00 00 00 10 00 00 00 03 00 00 00 b4 00 00 00 e6 00 00 00 03 00 00 00 01 00 00 00 01 00 00 00 20 00 00 00 30 00 00 00 50 00 00 00 64 00 00 00 80 00 00 00 40 00 00 00 dc 05 00 00 dc 05 00 00 10 00 00 00 10 00 00 00 20 00 00 00 20 00 00 00 10 00 00 00 10 00 00 00 10 00 00 00 10 00 00 00 10 00 00 00 10 00 00 00 10 00 00 00 10 00 00 00 00 00 00 00 40 00 00 00 80 00 00 00 40 00 00 00 20 00 00 00 00 00 00 00 08 00 00 00 10 00 00 00 18 00 00 00 1c 00 00 00 00 00 00 00 02 00 00 00 0e 00 00 00 15 00 00 00 20 00 00 00 24 00 00 00 2f 00 00 00 3a 00 00 00 00 00 00 00 03 00 00 00 0b 00 00 00 0e 00 00 00 16 00 00 00 18 00 00 00 20 00 00 00 26 00 00 00 80 00 00 00 40 00 00 00 64 00 00 00 64 00 00 00 00 00 00 00 c8 00 00 00 c8 00 00 00 c8 00 00 00 90 01 00 00 90 01 00 00 04 00 00 00 04 00 00 00 03 00 00 00 04 00 00 00 04 00 00 00 04 00 00 00 04 00 00 00 04 00 00 00 04 00 00 00 05 00 00 00 05 00 00 00 05 00 00 00 06 00 00 00 07 00 00 00 07 00 00 00 08 00 00 00 8c 00 00 00 05 00 00 00 f4 01 00 00 f4 01 00 00 f4 01 00 00 f4 01 00 00 58 02 00 00 84 03 00 00 84 03 00 00 84 03 00 00 0b 00 00 00 0f 00 00 00 0f 00 00 00 0e 00 00 00 0e 00 00 00 0c 00 00 00 0c 00 00 00 0c 00 00 00 9a 01 00 00 9a 01 00 00 9a 01 00 00 9a 01 00 00 9a 01 00 00 ae 01 00 00 ae 01 00 00 ae 01 00 00 3c 00 00 00 3c 00 00 00 3c 00 00 00 3c 00 00 00 3c 00 00 00 32 00 00 00 32 00 00 00 32 00 00 00 08 00 00 00 10 00 00 00 03 00 00 00 b4 00 00 00 e6 00 00 00 03 00 00 00 01 00 00 00 01 00 00 00 20 00 00 00 30 00 00 00 50 00 00 00 64 00 00 00 80 00 00 00 40 00 00 00 dc 05 00 00 dc 05 00 00 10 00 00 00 10 00 00 00 20 00 00 00 20 00 00 00 10 00 00 00 10 00 00 00 10 00 00 00 10 00 00 00 10 00 00 00 10 00 00 00 10 00 00 00 10 00 00 00 00 00 00 00 40 00 00 00 80 00 00 00 40 00 00 00 20 00 00 00 00 00 00 00 08 00 00 00 10 00 00 00 18 00 00 00 1c 00 00 00 00 00 00 00 02 00 00 00 0e 00 00 00 15 00 00 00 20 00 00 00 24 00 00 00 2f 00 00 00 3a 00 00 00 00 00 00 00 03 00 00 00 0b 00 00 00 0e 00 00 00 16 00 00 00 18 00 00 00 20 00 00 00 26 00 00 00 80 00 00 00 40 00 00 00];
		};
		iq_pfr {
			size = [d8 00 00 00];
			data = [00 00 00 00 00 00 00 00 00 00 00 00 00 00 00 00 00 00 00 00 08 00 00 00 70 00 00 00 e8 00 00 00 ff 00 00 00 ff 00 00 00 ff 00 00 00 ff 00 00 00 ff 00 00 00 ff 00 00 00 ff 00 00 00 af 00 00 00 91 00 00 00 01 00 00 00 91 00 00 00 af 00 00 00 e0 00 00 00 2c 01 00 00 e0 00 00 00 2c 01 00 00 e0 00 00 00 2c 01 00 00 e0 00 00 00 2c 01 00 00 e0 00 00 00 2c 01 00 00 e0 00 00 00 2c 01 00 00 e0 00 00 00 2c 01 00 00 e0 00 00 00 2c 01 00 00 e0 00 00 00 2c 01 00 00 e0 00 00 00 2c 01 00 00 e0 00 00 00 2c 01 00 00 e0 00 00 00 2c 01 00 00 e0 00 00 00 2c 01 00 00 e0 00 00 00 2c 01 00 00 e0 00 00 00 2c 01 00 00 e0 00 00 00 2c 01 00 00 e0 00 00 00 2c 01 00 00];
		};
		iq_wdr {
			size = [e4 02 00 00];
			data = [01 00 00 00 01 00 00 00 20 00 00 00 12 00 00 00 a0 00 00 00 05 00 00 00 03 00 00 00 00 00 00 00 01 00 00 00 02 00 00 00 06 00 00 00 0e 00 00 00 16 00 00 00 1e 00 00 00 22 00 00 00 26 00 00 00 28 00 00 00 2a 00 00 00 2b 00 00 00 2c 00 00 00 2d 00 00 00 2e 00 00 00 2f 00 00 00 30 00 00 00 31 00 00 00 32 00 00 00 33 00 00 00 34 00 00 00 35 00 00 00 36 00 00 00 37 00 00 00 38 00 00 00 39 00 00 00 3a 00 00 00 3b 00 00 00 3c 00 00 00 3d 00 00 00 3e 00 00 00 3f 00 00 00 00 00 00 00 00 00 00 00 02 00 00 00 03 00 00 00 03 00 00 00 03 00 00 00 02 00 00 00 02 00 00 00 01 00 00 00 01 00 00 00 00 00 00 00 00 00 00 00 00 00 00 00 00 00 00 00 00 00 00 00 00 00 00 00 00 00 00 00 00 00 00 00 00 00 00 00 00 00 00 00 00 00 00 00 00 00 00 00 00 00 00 00 00 00 00 00 00 00 00 00 00 00 00 00 00 00 00 00 00 00 00 00 00 00 00 00 00 00 00 00 00 00 00 00 00 00 00 00 ff 0f 00 00 f9 0f 00 00 b6 0f 00 00 92 0f 00 00 64 0f 00 00 2b 0f 00 00 e8 0e 00 00 c2 0e 00 00 99 0e 00 00 6e 0e 00 00 40 0e 00 00 10 0e 00 00 de 0d 00 00 aa 0d 00 00 74 0d 00 00 3d 0d 00 00 04 0d 00 00 cb 0c 00 00 90 0c 00 00 55 0c 00 00 1a 0c 00 00 de 0b 00 00 a3 0b 00 00 68 0b 00 00 2d 0b 00 00 f3 0a 00 00 bb 0a 00 00 83 0a 00 00 4c 0a 00 00 17 0a 00 00 e2 09 00 00 7e 09 00 00 20 09 00 00 c9 08 00 00 77 08 00 00 2c 08 00 00 e7 07 00 00 a7 07 00 00 6c 07 00 00 06 07 00 00 b1 06 00 00 6a 06 00 00 2f 06 00 00 d4 05 00 00 94 05 00 00 66 05 00 00 45 05 00 00 2c 05 00 00 19 05 00 00 0b 05 00 00 00 05 00 00 f7 04 00 00 f0 04 00 00 eb 04 00 00 e6 04 00 00 e3 04 00 00 df 04 00 00 dd 04 00 00 db 04 00 00 d9 04 00 00 d8 04 00 00 d6 04 00 00 d5 04 00 00 d4 04 00 00 d3 04 00 00 8c 00 00 00 40 00 00 00 00 00 00 00 ff 00 00 00 40 00 00 00 00 00 00 00 ff 00 00 00 40 00 00 00 00 00 00 00 ff 00 00 00 40 00 00 00 00 00 00 00 ff 00 00 00 40 00 00 00 00 00 00 00 ff 00 00 00 40 00 00 00 00 00 00 00 ff 00 00 00 40 00 00 00 00 00 00 00 ff 00 00 00 40 00 00 00 00 00 00 00 ff 00 00 00 40 00 00 00 00 00 00 00 ff 00 00 00 40 00 00 00 00 00 00 00 ff 00 00 00 40 00 00 00 00 00 00 00 ff 00 00 00 40 00 00 00 00 00 00 00 ff 00 00 00 40 00 00 00 00 00 00 00 ff 00 00 00 40 00 00 00 00 00 00 00 ff 00 00 00 40 00 00 00 00 00 00 00 ff 00 00 00 40 00 00 00 00 00 00 00 ff 00 00 00];
		};
		iq_defog {
			size = [84 00 00 00];
			data = [00 00 00 00 01 00 00 00 01 00 00 00 07 00 00 03 ff 60 c0 c0 c0 c0 c0 c0 c0 c0 c0 c0 c0 c0 c0 c0 c0 c0 c0 00 28 00 00 03 ff 80 28 00 00 03 ff 80 28 00 00 03 ff 80 28 00 00 03 ff 80 28 00 00 03 ff 80 28 00 00 03 ff 80 28 00 00 03 ff 80 28 00 00 03 ff 80 28 00 00 03 ff 80 28 00 00 03 ff 80 28 00 00 03 ff 80 28 00 00 03 ff 80 28 00 00 03 ff 80 28 00 00 03 ff 80 28 00 00 03 ff 80 28 00 00 03 ff 80];
		};
		iq_shdr {
			size = [f0 01 00 00];
			data = [01 00 00 00 01 00 00 00 10 00 00 00 01 00 00 00 00 0c 09 00 c0 00 06 00 01 00 00 00 00 08 0a 00 80 00 07 00 02 00 00 02 04 08 0a 0c 0e 10 0e 0c 0a 08 06 04 02 00 00 00 00 00 00 00 00 00 08 10 18 1c 20 24 26 28 29 2a 2b 2c 2d 2e 2f 30 31 32 33 34 35 36 37 38 39 3a 3b 3c 3d 3e 3f 03 03 03 02 02 02 01 01 00 00 00 00 00 00 00 00 00 00 00 00 00 00 00 00 00 00 00 00 00 00 00 00 00 00 00 75 00 e0 00 43 01 9e 01 f3 01 43 02 8e 02 d5 02 18 03 58 03 95 03 cf 03 06 04 3b 04 6e 04 9e 04 ce 04 fb 04 27 05 51 05 7a 05 a1 05 c8 05 ed 05 34 06 78 06 b8 06 f5 06 2f 07 67 07 9c 07 cf 07 ff 07 2e 08 5b 08 86 08 d7 08 22 09 66 09 a6 09 17 0a 78 0a cd 0a 17 0b 58 0b 93 0b c8 0b f9 0b 28 0c 56 0c 84 0c b2 0c e3 0c 16 0d 4c 0d 87 0d c5 0d 08 0e 50 0e 9c 0e ee 0e 44 0f 9f 0f ff 0f ff 03 04 05 06 07 08 08 00 00 01 02 03 00 e0 00 04 05 06 07 08 08 00 00 01 02 03 00 e0 00 04 05 06 07 08 08 00 00 01 02 03 00 e0 00 04 05 06 07 08 08 00 00 01 02 03 00 e0 00 04 05 06 07 08 08 00 00 01 02 03 00 e0 00 04 05 06 07 08 08 00 00 01 02 03 00 e0 00 04 05 06 07 08 08 00 00 01 02 03 00 e0 00 04 05 06 07 08 08 00 00 01 02 03 00 e0 00 04 05 06 07 08 08 00 00 01 02 03 00 e0 00 04 05 06 07 08 08 00 00 01 02 03 00 e0 00 04 05 06 07 08 08 00 00 01 02 03 00 e0 00 04 05 06 07 08 08 00 00 01 02 03 00 e0 00 04 05 06 07 08 08 00 00 01 02 03 00 e0 00 04 05 06 07 08 08 00 00 01 02 03 00 e0 00 04 05 06 07 08 08 00 00 01 02 03 00 e0 00 04 05 06 07 08 08 00 00 01 02 03 00 e0 00 04 05 06 07 08 08 00 00 01 02 03 00 00 00];
		};
		iq_rgbir {
			size = [28 00 00 00];
			data = [00 00 00 00 cc 00 00 00 cc 00 00 00 e6 00 00 00 00 01 00 00 cc 00 00 00 cc 00 00 00 e6 00 00 00 dc 00 00 00 f0 00 00 00];
		};
		iq_companding {
			size = [18 01 00 00];
			data = [00 02 00 00 00 03 00 00 00 0a 00 00 ff 0f 00 00 ff 0f 00 00 ff 0f 00 00 ff 0f 00 00 ff 0f 00 00 ff 0f 00 00 ff 0f 00 00 ff 0f 00 00 00 00 00 00 00 01 00 00 00 02 00 00 00 08 00 00 00 08 00 00 00 08 00 00 00 08 00 00 00 08 00 00 00 08 00 00 00 08 00 00 00 08 00 00 00 08 00 00 04 00 00 00 05 00 00 00 06 00 00 00 08 00 00 00 08 00 00 00 08 00 00 00 08 00 00 00 08 00 00 00 08 00 00 00 08 00 00 00 08 00 00 00 08 00 00 00 0a 00 00 00 0b 00 00 00 0c 00 00 00 0d 00 00 00 0e 00 00 00 0f 00 00 00 10 00 00 00 10 00 00 00 10 00 00 00 10 00 00 00 10 00 00 00 00 00 00 00 00 02 00 00 00 04 00 00 00 06 00 00 00 08 00 00 00 0a 00 00 00 0c 00 00 00 0c 00 00 00 0c 00 00 00 0c 00 00 00 0c 00 00 00 0c 00 00 03 00 00 00 04 00 00 00 05 00 00 00 06 00 00 00 07 00 00 00 08 00 00 00 09 00 00 00 09 00 00 00 09 00 00 00 09 00 00 00 09 00 00 00 09 00 00 00];
		};
		iq_post_3dnr {
			size = [40 02 00 00];
			data = [01 00 00 00 00 00 00 00 01 00 00 00 06 08 0a 10 08 00 10 10 10 01 02 01 01 02 01 0a 0f 14 0a 0f 14 01 03 01 01 03 01 0a 0f 14 0a 0f 14 02 03 04 10 08 00 04 04 04 01 02 01 01 02 01 0a 0f 14 0a 0f 14 01 03 01 01 03 01 0a 0f 14 0a 0f 14 02 03 04 10 08 00 04 04 04 01 02 01 01 02 01 0f 14 19 0f 14 19 01 03 01 01 03 01 0f 14 19 0f 14 19 03 04 05 10 08 00 05 04 04 01 02 01 01 02 01 14 1e 28 14 1e 28 01 03 01 01 03 01 14 1e 28 14 1e 28 04 05 06 10 08 00 06 08 08 01 03 01 01 03 01 1e 28 32 1e 28 32 01 03 01 01 03 01 1e 28 32 1e 28 32 05 06 07 10 08 00 07 08 08 01 03 01 01 03 01 28 32 3c 28 32 3c 01 03 01 01 03 01 28 32 3c 28 32 3c 06 07 08 10 08 00 08 10 10 01 03 01 01 03 01 32 3c 46 32 3c 46 01 03 01 01 03 01 32 3c 46 32 3c 46 07 08 09 10 08 00 09 10 10 01 03 01 01 03 01 3c 46 50 3c 46 50 01 03 01 01 03 01 3c 46 50 3c 46 50 08 09 0a 10 08 00 0a 10 10 01 03 01 01 03 01 46 50 5a 46 50 5a 01 03 01 01 03 01 46 50 5a 46 50 5a 09 0a 0b 10 08 00 0b 10 10 01 03 01 01 03 01 50 5a 64 50 5a 64 01 03 01 01 03 01 50 5a 64 50 5a 64 0a 0b 0c 10 08 00 0c 10 10 01 03 01 01 03 01 5a 64 6e 5a 64 6e 01 03 01 01 03 01 5a 64 6e 5a 64 6e 0b 0c 0d 10 08 00 0d 10 10 01 03 01 01 03 01 64 78 8c 64 78 8c 01 03 01 01 03 01 64 78 8c 64 78 8c 0c 0d 0e 10 08 00 0d 10 10 01 03 01 01 03 01 64 78 8c 64 78 8c 01 03 01 01 03 01 64 78 8c 64 78 8c 0d 0e 0f 10 08 00 0d 10 10 01 03 01 01 03 01 64 78 8c 64 78 8c 01 03 01 01 03 01 64 78 8c 64 78 8c 0e 0f 10 10 08 00 0d 10 10 01 03 01 01 03 01 64 78 8c 64 78 8c 01 03 01 01 03 01 64 78 8c 64 78 8c 0f 10 11 10 08 00 0d 10 10 01 03 01 01 03 01 64 78 8c 64 78 8c 01 03 01 01 03 01 64 78 8c 64 78 8c 0f 10 11 10 08 00 0d 10 10 01 03 01 01 03 01 64 78 8c 64 78 8c 01 03 01 01 03 01 64 78 8c 64 78 8c 00 00 00];
		};
	};
};
